// *************************************************************************** *
// *                                                                           *
// *                      Mentor Graphics Corporation                          *
// *                          All rights reserved                              *
// *                                                                           *
// *************************************************************************** *
// *                                                                           *
// * Description:         CANDB File                                           *
// * Generated at:        2021-02-26 13:32                                     *
// * System:              SPA4710_Final2                                       *
// * Variant:             ConfigurationsSPA3AD_prototype                       *
// * Network:             Mid6CANFD                                            *
// *                                                                           *
// *************************************************************************** *
// *                                                                           *
// *             THIS CONFIGURATION MIGHT CONTAIN SOME ERRORS                  *
// *              IF THE INPUT MODEL WAS NOT PROPERLY FORMED!                  *
// *                    Do Not Use this File directly!                         *
// *                                                                           *
// *************************************************************************** *
VERSION "Mid6CANFD"

NS_ :

BS_ :

BU_ :  ETC SSMB VIMB

BO_ 283 VIMBMid6CanFdFr22 : 64 VIMB
 SG_ AdSecPSSGroupSafe3_UB : 511|1@0+ (1,0) [0|1] "" SSMB
 SG_ AdSecPSSGroupSafe3Chks : 0|16@1+ (1.0,0.0) [0.0|65535.0] "Unitless" SSMB
 SG_ AdSecPSSGroupSafe3Cntr : 16|8@1+ (1.0,0.0) [0.0|255.0] "Unitless" SSMB
 SG_ AdSecPSSGroupSafe3DataID : 24|16@1+ (1.0,0.0) [0.0|65535.0] "Unitless" SSMB
 SG_ AdSecPSSGroupSafe3DeltaTPos1 : 40|18@1+ (0.000001,0.0) [0.0|0.262] "s" SSMB
 SG_ AdSecPSSGroupSafe3DeltaTPos2 : 64|18@1+ (0.000001,0.0) [0.0|0.262] "s" SSMB
 SG_ AdSecPSSGroupSafe3DeltaTPos3 : 88|18@1+ (0.000001,0.0) [0.0|0.262] "s" SSMB
 SG_ AdSecPSSGroupSafe3DeltaTPos4 : 112|18@1+ (0.000001,0.0) [0.0|0.262] "s" SSMB
 SG_ AdSecPSSGroupSafe3DeltaTPos5 : 136|18@1+ (0.000001,0.0) [0.0|0.262] "s" SSMB
 SG_ AdSecPSSGroupSafe3DeltaTPos6 : 160|18@1+ (0.000001,0.0) [0.0|0.262] "s" SSMB
 SG_ AdSecPSSGroupSafe3DeltaXPos1 : 184|18@1+ (0.0001,-13.107) [-13.107|13.107000000000003] "m" SSMB
 SG_ AdSecPSSGroupSafe3DeltaXPos2 : 202|18@1+ (0.0001,-13.107) [-13.107|13.107000000000003] "m" SSMB
 SG_ AdSecPSSGroupSafe3DeltaXPos3 : 220|18@1+ (0.0001,-13.107) [-13.107|13.107000000000003] "m" SSMB
 SG_ AdSecPSSGroupSafe3DeltaXPos4 : 238|18@1+ (0.0001,-13.107) [-13.107|13.107000000000003] "m" SSMB
 SG_ AdSecPSSGroupSafe3DeltaXPos5 : 256|18@1+ (0.0001,-13.107) [-13.107|13.107000000000003] "m" SSMB
 SG_ AdSecPSSGroupSafe3DeltaXPos6 : 274|18@1+ (0.0001,-13.107) [-13.107|13.107000000000003] "m" SSMB
 SG_ AdSecPSSGroupSafe3DeltaYPos1 : 292|18@1+ (0.0001,-13.107) [-13.107|13.107000000000003] "m" SSMB
 SG_ AdSecPSSGroupSafe3DeltaYPos2 : 310|18@1+ (0.0001,-13.107) [-13.107|13.107000000000003] "m" SSMB
 SG_ AdSecPSSGroupSafe3DeltaYPos3 : 328|18@1+ (0.0001,-13.107) [-13.107|13.107000000000003] "m" SSMB
 SG_ AdSecPSSGroupSafe3DeltaYPos4 : 346|18@1+ (0.0001,-13.107) [-13.107|13.107000000000003] "m" SSMB
 SG_ AdSecPSSGroupSafe3DeltaYPos5 : 364|18@1+ (0.0001,-13.107) [-13.107|13.107000000000003] "m" SSMB
 SG_ AdSecPSSGroupSafe3DeltaYPos6 : 382|18@1+ (0.0001,-13.107) [-13.107|13.107000000000003] "m" SSMB
 SG_ AdSecPSSGroupSafe3HeadingPos1 : 400|16@1+ (0.0001,-3.2767) [-3.2767|3.2768000000000006] "rad" SSMB
 SG_ AdSecPSSGroupSafe3HeadingPos2 : 416|16@1+ (0.0001,-3.2767) [-3.2767|3.2768000000000006] "rad" SSMB
 SG_ AdSecPSSGroupSafe3HeadingPos3 : 432|16@1+ (0.0001,-3.2767) [-3.2767|3.2768000000000006] "rad" SSMB
 SG_ AdSecPSSGroupSafe3HeadingPos4 : 448|16@1+ (0.0001,-3.2767) [-3.2767|3.2768000000000006] "rad" SSMB
 SG_ AdSecPSSGroupSafe3HeadingPos5 : 464|16@1+ (0.0001,-3.2767) [-3.2767|3.2768000000000006] "rad" SSMB
 SG_ AdSecPSSGroupSafe3HeadingPos6 : 480|16@1+ (0.0001,-3.2767) [-3.2767|3.2768000000000006] "rad" SSMB
 SG_ AdSecPSSGroupSafe3TrajectID : 496|4@1+ (1.0,0.0) [0.0|15.0] "Unitless" SSMB

BO_ 286 VIMBMid6CanFdFr23 : 64 VIMB
 SG_ AdSecPSSGroupSafe4_UB : 511|1@0+ (1,0) [0|1] "" SSMB
 SG_ AdSecPSSGroupSafe4Chks : 0|16@1+ (1.0,0.0) [0.0|65535.0] "Unitless" SSMB
 SG_ AdSecPSSGroupSafe4Cntr : 16|8@1+ (1.0,0.0) [0.0|255.0] "Unitless" SSMB
 SG_ AdSecPSSGroupSafe4DataID : 24|16@1+ (1.0,0.0) [0.0|65535.0] "Unitless" SSMB
 SG_ AdSecPSSGroupSafe4DeltaTPos1 : 40|18@1+ (0.000001,0.0) [0.0|0.262] "s" SSMB
 SG_ AdSecPSSGroupSafe4DeltaTPos2 : 64|18@1+ (0.000001,0.0) [0.0|0.262] "s" SSMB
 SG_ AdSecPSSGroupSafe4DeltaTPos3 : 88|18@1+ (0.000001,0.0) [0.0|0.262] "s" SSMB
 SG_ AdSecPSSGroupSafe4DeltaTPos4 : 112|18@1+ (0.000001,0.0) [0.0|0.262] "s" SSMB
 SG_ AdSecPSSGroupSafe4DeltaTPos5 : 136|18@1+ (0.000001,0.0) [0.0|0.262] "s" SSMB
 SG_ AdSecPSSGroupSafe4DeltaTPos6 : 160|18@1+ (0.000001,0.0) [0.0|0.262] "s" SSMB
 SG_ AdSecPSSGroupSafe4DeltaXPos1 : 184|18@1+ (0.0001,-13.107) [-13.107|13.107000000000003] "m" SSMB
 SG_ AdSecPSSGroupSafe4DeltaXPos2 : 202|18@1+ (0.0001,-13.107) [-13.107|13.107000000000003] "m" SSMB
 SG_ AdSecPSSGroupSafe4DeltaXPos3 : 220|18@1+ (0.0001,-13.107) [-13.107|13.107000000000003] "m" SSMB
 SG_ AdSecPSSGroupSafe4DeltaXPos4 : 238|18@1+ (0.0001,-13.107) [-13.107|13.107000000000003] "m" SSMB
 SG_ AdSecPSSGroupSafe4DeltaXPos5 : 256|18@1+ (0.0001,-13.107) [-13.107|13.107000000000003] "m" SSMB
 SG_ AdSecPSSGroupSafe4DeltaXPos6 : 274|18@1+ (0.0001,-13.107) [-13.107|13.107000000000003] "m" SSMB
 SG_ AdSecPSSGroupSafe4DeltaYPos1 : 292|18@1+ (0.0001,-13.107) [-13.107|13.107000000000003] "m" SSMB
 SG_ AdSecPSSGroupSafe4DeltaYPos2 : 310|18@1+ (0.0001,-13.107) [-13.107|13.107000000000003] "m" SSMB
 SG_ AdSecPSSGroupSafe4DeltaYPos3 : 328|18@1+ (0.0001,-13.107) [-13.107|13.107000000000003] "m" SSMB
 SG_ AdSecPSSGroupSafe4DeltaYPos4 : 346|18@1+ (0.0001,-13.107) [-13.107|13.107000000000003] "m" SSMB
 SG_ AdSecPSSGroupSafe4DeltaYPos5 : 364|18@1+ (0.0001,-13.107) [-13.107|13.107000000000003] "m" SSMB
 SG_ AdSecPSSGroupSafe4DeltaYPos6 : 382|18@1+ (0.0001,-13.107) [-13.107|13.107000000000003] "m" SSMB
 SG_ AdSecPSSGroupSafe4HeadingPos1 : 400|16@1+ (0.0001,-3.2767) [-3.2767|3.2768000000000006] "rad" SSMB
 SG_ AdSecPSSGroupSafe4HeadingPos2 : 416|16@1+ (0.0001,-3.2767) [-3.2767|3.2768000000000006] "rad" SSMB
 SG_ AdSecPSSGroupSafe4HeadingPos3 : 432|16@1+ (0.0001,-3.2767) [-3.2767|3.2768000000000006] "rad" SSMB
 SG_ AdSecPSSGroupSafe4HeadingPos4 : 448|16@1+ (0.0001,-3.2767) [-3.2767|3.2768000000000006] "rad" SSMB
 SG_ AdSecPSSGroupSafe4HeadingPos5 : 464|16@1+ (0.0001,-3.2767) [-3.2767|3.2768000000000006] "rad" SSMB
 SG_ AdSecPSSGroupSafe4HeadingPos6 : 480|16@1+ (0.0001,-3.2767) [-3.2767|3.2768000000000006] "rad" SSMB
 SG_ AdSecPSSGroupSafe4TrajectID : 496|4@1+ (1.0,0.0) [0.0|15.0] "Unitless" SSMB

BO_ 289 VIMBMid6CanFdFr24 : 64 VIMB
 SG_ AdSecPSSGroupSafe5_UB : 511|1@0+ (1,0) [0|1] "" SSMB
 SG_ AdSecPSSGroupSafe5Chks : 0|16@1+ (1.0,0.0) [0.0|65535.0] "Unitless" SSMB
 SG_ AdSecPSSGroupSafe5Cntr : 16|8@1+ (1.0,0.0) [0.0|255.0] "Unitless" SSMB
 SG_ AdSecPSSGroupSafe5DataID : 24|16@1+ (1.0,0.0) [0.0|65535.0] "Unitless" SSMB
 SG_ AdSecPSSGroupSafe5DeltaTPos1 : 40|18@1+ (0.000001,0.0) [0.0|0.262] "s" SSMB
 SG_ AdSecPSSGroupSafe5DeltaTPos2 : 64|18@1+ (0.000001,0.0) [0.0|0.262] "s" SSMB
 SG_ AdSecPSSGroupSafe5DeltaTPos3 : 88|18@1+ (0.000001,0.0) [0.0|0.262] "s" SSMB
 SG_ AdSecPSSGroupSafe5DeltaTPos4 : 112|18@1+ (0.000001,0.0) [0.0|0.262] "s" SSMB
 SG_ AdSecPSSGroupSafe5DeltaTPos5 : 136|18@1+ (0.000001,0.0) [0.0|0.262] "s" SSMB
 SG_ AdSecPSSGroupSafe5DeltaTPos6 : 160|18@1+ (0.000001,0.0) [0.0|0.262] "s" SSMB
 SG_ AdSecPSSGroupSafe5DeltaXPos1 : 184|18@1+ (0.0001,-13.107) [-13.107|13.107000000000003] "m" SSMB
 SG_ AdSecPSSGroupSafe5DeltaXPos2 : 202|18@1+ (0.0001,-13.107) [-13.107|13.107000000000003] "m" SSMB
 SG_ AdSecPSSGroupSafe5DeltaXPos3 : 220|18@1+ (0.0001,-13.107) [-13.107|13.107000000000003] "m" SSMB
 SG_ AdSecPSSGroupSafe5DeltaXPos4 : 238|18@1+ (0.0001,-13.107) [-13.107|13.107000000000003] "m" SSMB
 SG_ AdSecPSSGroupSafe5DeltaXPos5 : 256|18@1+ (0.0001,-13.107) [-13.107|13.107000000000003] "m" SSMB
 SG_ AdSecPSSGroupSafe5DeltaXPos6 : 274|18@1+ (0.0001,-13.107) [-13.107|13.107000000000003] "m" SSMB
 SG_ AdSecPSSGroupSafe5DeltaYPos1 : 292|18@1+ (0.0001,-13.107) [-13.107|13.107000000000003] "m" SSMB
 SG_ AdSecPSSGroupSafe5DeltaYPos2 : 310|18@1+ (0.0001,-13.107) [-13.107|13.107000000000003] "m" SSMB
 SG_ AdSecPSSGroupSafe5DeltaYPos3 : 328|18@1+ (0.0001,-13.107) [-13.107|13.107000000000003] "m" SSMB
 SG_ AdSecPSSGroupSafe5DeltaYPos4 : 346|18@1+ (0.0001,-13.107) [-13.107|13.107000000000003] "m" SSMB
 SG_ AdSecPSSGroupSafe5DeltaYPos5 : 364|18@1+ (0.0001,-13.107) [-13.107|13.107000000000003] "m" SSMB
 SG_ AdSecPSSGroupSafe5DeltaYPos6 : 382|18@1+ (0.0001,-13.107) [-13.107|13.107000000000003] "m" SSMB
 SG_ AdSecPSSGroupSafe5HeadingPos1 : 400|16@1+ (0.0001,-3.2767) [-3.2767|3.2768000000000006] "rad" SSMB
 SG_ AdSecPSSGroupSafe5HeadingPos2 : 416|16@1+ (0.0001,-3.2767) [-3.2767|3.2768000000000006] "rad" SSMB
 SG_ AdSecPSSGroupSafe5HeadingPos3 : 432|16@1+ (0.0001,-3.2767) [-3.2767|3.2768000000000006] "rad" SSMB
 SG_ AdSecPSSGroupSafe5HeadingPos4 : 448|16@1+ (0.0001,-3.2767) [-3.2767|3.2768000000000006] "rad" SSMB
 SG_ AdSecPSSGroupSafe5HeadingPos5 : 464|16@1+ (0.0001,-3.2767) [-3.2767|3.2768000000000006] "rad" SSMB
 SG_ AdSecPSSGroupSafe5HeadingPos6 : 480|16@1+ (0.0001,-3.2767) [-3.2767|3.2768000000000006] "rad" SSMB
 SG_ AdSecPSSGroupSafe5TrajectID : 496|4@1+ (1.0,0.0) [0.0|15.0] "Unitless" SSMB

BO_ 292 VIMBMid6CanFdFr25 : 64 VIMB
 SG_ AdSecPSSGroupSafe6_UB : 511|1@0+ (1,0) [0|1] "" SSMB
 SG_ AdSecPSSGroupSafe6Chks : 0|16@1+ (1.0,0.0) [0.0|65535.0] "Unitless" SSMB
 SG_ AdSecPSSGroupSafe6Cntr : 16|8@1+ (1.0,0.0) [0.0|255.0] "Unitless" SSMB
 SG_ AdSecPSSGroupSafe6DataID : 24|16@1+ (1.0,0.0) [0.0|65535.0] "Unitless" SSMB
 SG_ AdSecPSSGroupSafe6DeltaTPos1 : 40|18@1+ (0.000001,0.0) [0.0|0.262] "s" SSMB
 SG_ AdSecPSSGroupSafe6DeltaTPos2 : 64|18@1+ (0.000001,0.0) [0.0|0.262] "s" SSMB
 SG_ AdSecPSSGroupSafe6DeltaTPos3 : 88|18@1+ (0.000001,0.0) [0.0|0.262] "s" SSMB
 SG_ AdSecPSSGroupSafe6DeltaTPos4 : 112|18@1+ (0.000001,0.0) [0.0|0.262] "s" SSMB
 SG_ AdSecPSSGroupSafe6DeltaTPos5 : 136|18@1+ (0.000001,0.0) [0.0|0.262] "s" SSMB
 SG_ AdSecPSSGroupSafe6DeltaTPos6 : 160|18@1+ (0.000001,0.0) [0.0|0.262] "s" SSMB
 SG_ AdSecPSSGroupSafe6DeltaXPos1 : 184|18@1+ (0.0001,-13.107) [-13.107|13.107000000000003] "m" SSMB
 SG_ AdSecPSSGroupSafe6DeltaXPos2 : 202|18@1+ (0.0001,-13.107) [-13.107|13.107000000000003] "m" SSMB
 SG_ AdSecPSSGroupSafe6DeltaXPos3 : 220|18@1+ (0.0001,-13.107) [-13.107|13.107000000000003] "m" SSMB
 SG_ AdSecPSSGroupSafe6DeltaXPos4 : 238|18@1+ (0.0001,-13.107) [-13.107|13.107000000000003] "m" SSMB
 SG_ AdSecPSSGroupSafe6DeltaXPos5 : 256|18@1+ (0.0001,-13.107) [-13.107|13.107000000000003] "m" SSMB
 SG_ AdSecPSSGroupSafe6DeltaXPos6 : 274|18@1+ (0.0001,-13.107) [-13.107|13.107000000000003] "m" SSMB
 SG_ AdSecPSSGroupSafe6DeltaYPos1 : 292|18@1+ (0.0001,-13.107) [-13.107|13.107000000000003] "m" SSMB
 SG_ AdSecPSSGroupSafe6DeltaYPos2 : 310|18@1+ (0.0001,-13.107) [-13.107|13.107000000000003] "m" SSMB
 SG_ AdSecPSSGroupSafe6DeltaYPos3 : 328|18@1+ (0.0001,-13.107) [-13.107|13.107000000000003] "m" SSMB
 SG_ AdSecPSSGroupSafe6DeltaYPos4 : 346|18@1+ (0.0001,-13.107) [-13.107|13.107000000000003] "m" SSMB
 SG_ AdSecPSSGroupSafe6DeltaYPos5 : 364|18@1+ (0.0001,-13.107) [-13.107|13.107000000000003] "m" SSMB
 SG_ AdSecPSSGroupSafe6DeltaYPos6 : 382|18@1+ (0.0001,-13.107) [-13.107|13.107000000000003] "m" SSMB
 SG_ AdSecPSSGroupSafe6HeadingPos1 : 400|16@1+ (0.0001,-3.2767) [-3.2767|3.2768000000000006] "rad" SSMB
 SG_ AdSecPSSGroupSafe6HeadingPos2 : 416|16@1+ (0.0001,-3.2767) [-3.2767|3.2768000000000006] "rad" SSMB
 SG_ AdSecPSSGroupSafe6HeadingPos3 : 432|16@1+ (0.0001,-3.2767) [-3.2767|3.2768000000000006] "rad" SSMB
 SG_ AdSecPSSGroupSafe6HeadingPos4 : 448|16@1+ (0.0001,-3.2767) [-3.2767|3.2768000000000006] "rad" SSMB
 SG_ AdSecPSSGroupSafe6HeadingPos5 : 464|16@1+ (0.0001,-3.2767) [-3.2767|3.2768000000000006] "rad" SSMB
 SG_ AdSecPSSGroupSafe6HeadingPos6 : 480|16@1+ (0.0001,-3.2767) [-3.2767|3.2768000000000006] "rad" SSMB
 SG_ AdSecPSSGroupSafe6TrajectID : 496|4@1+ (1.0,0.0) [0.0|15.0] "Unitless" SSMB

BO_ 295 VIMBMid6CanFdFr26 : 64 VIMB
 SG_ AdSecPSSGroupSafe7_UB : 511|1@0+ (1,0) [0|1] "" SSMB
 SG_ AdSecPSSGroupSafe7Chks : 0|16@1+ (1.0,0.0) [0.0|65535.0] "Unitless" SSMB
 SG_ AdSecPSSGroupSafe7Cntr : 16|8@1+ (1.0,0.0) [0.0|255.0] "Unitless" SSMB
 SG_ AdSecPSSGroupSafe7DataID : 24|16@1+ (1.0,0.0) [0.0|65535.0] "Unitless" SSMB
 SG_ AdSecPSSGroupSafe7DeltaTPos1 : 40|18@1+ (0.000001,0.0) [0.0|0.262] "s" SSMB
 SG_ AdSecPSSGroupSafe7DeltaTPos2 : 64|18@1+ (0.000001,0.0) [0.0|0.262] "s" SSMB
 SG_ AdSecPSSGroupSafe7DeltaTPos3 : 88|18@1+ (0.000001,0.0) [0.0|0.262] "s" SSMB
 SG_ AdSecPSSGroupSafe7DeltaTPos4 : 112|18@1+ (0.000001,0.0) [0.0|0.262] "s" SSMB
 SG_ AdSecPSSGroupSafe7DeltaTPos5 : 136|18@1+ (0.000001,0.0) [0.0|0.262] "s" SSMB
 SG_ AdSecPSSGroupSafe7DeltaTPos6 : 160|18@1+ (0.000001,0.0) [0.0|0.262] "s" SSMB
 SG_ AdSecPSSGroupSafe7DeltaXPos1 : 184|18@1+ (0.0001,-13.107) [-13.107|13.107000000000003] "m" SSMB
 SG_ AdSecPSSGroupSafe7DeltaXPos2 : 202|18@1+ (0.0001,-13.107) [-13.107|13.107000000000003] "m" SSMB
 SG_ AdSecPSSGroupSafe7DeltaXPos3 : 220|18@1+ (0.0001,-13.107) [-13.107|13.107000000000003] "m" SSMB
 SG_ AdSecPSSGroupSafe7DeltaXPos4 : 238|18@1+ (0.0001,-13.107) [-13.107|13.107000000000003] "m" SSMB
 SG_ AdSecPSSGroupSafe7DeltaXPos5 : 256|18@1+ (0.0001,-13.107) [-13.107|13.107000000000003] "m" SSMB
 SG_ AdSecPSSGroupSafe7DeltaXPos6 : 274|18@1+ (0.0001,-13.107) [-13.107|13.107000000000003] "m" SSMB
 SG_ AdSecPSSGroupSafe7DeltaYPos1 : 292|18@1+ (0.0001,-13.107) [-13.107|13.107000000000003] "m" SSMB
 SG_ AdSecPSSGroupSafe7DeltaYPos2 : 310|18@1+ (0.0001,-13.107) [-13.107|13.107000000000003] "m" SSMB
 SG_ AdSecPSSGroupSafe7DeltaYPos3 : 328|18@1+ (0.0001,-13.107) [-13.107|13.107000000000003] "m" SSMB
 SG_ AdSecPSSGroupSafe7DeltaYPos4 : 346|18@1+ (0.0001,-13.107) [-13.107|13.107000000000003] "m" SSMB
 SG_ AdSecPSSGroupSafe7DeltaYPos5 : 364|18@1+ (0.0001,-13.107) [-13.107|13.107000000000003] "m" SSMB
 SG_ AdSecPSSGroupSafe7DeltaYPos6 : 382|18@1+ (0.0001,-13.107) [-13.107|13.107000000000003] "m" SSMB
 SG_ AdSecPSSGroupSafe7HeadingPos1 : 400|16@1+ (0.0001,-3.2767) [-3.2767|3.2768000000000006] "rad" SSMB
 SG_ AdSecPSSGroupSafe7HeadingPos2 : 416|16@1+ (0.0001,-3.2767) [-3.2767|3.2768000000000006] "rad" SSMB
 SG_ AdSecPSSGroupSafe7HeadingPos3 : 432|16@1+ (0.0001,-3.2767) [-3.2767|3.2768000000000006] "rad" SSMB
 SG_ AdSecPSSGroupSafe7HeadingPos4 : 448|16@1+ (0.0001,-3.2767) [-3.2767|3.2768000000000006] "rad" SSMB
 SG_ AdSecPSSGroupSafe7HeadingPos5 : 464|16@1+ (0.0001,-3.2767) [-3.2767|3.2768000000000006] "rad" SSMB
 SG_ AdSecPSSGroupSafe7HeadingPos6 : 480|16@1+ (0.0001,-3.2767) [-3.2767|3.2768000000000006] "rad" SSMB
 SG_ AdSecPSSGroupSafe7TrajectID : 496|4@1+ (1.0,0.0) [0.0|15.0] "Unitless" SSMB

BO_ 296 VIMBMid6CanFdFr27 : 64 VIMB
 SG_ AdSecPSSGroupSafe8_UB : 511|1@0+ (1,0) [0|1] "" SSMB
 SG_ AdSecPSSGroupSafe8Chks : 0|16@1+ (1.0,0.0) [0.0|65535.0] "Unitless" SSMB
 SG_ AdSecPSSGroupSafe8Cntr : 16|8@1+ (1.0,0.0) [0.0|255.0] "Unitless" SSMB
 SG_ AdSecPSSGroupSafe8DataID : 24|16@1+ (1.0,0.0) [0.0|65535.0] "Unitless" SSMB
 SG_ AdSecPSSGroupSafe8DeltaTPos1 : 40|18@1+ (0.000001,0.0) [0.0|0.262] "s" SSMB
 SG_ AdSecPSSGroupSafe8DeltaTPos2 : 64|18@1+ (0.000001,0.0) [0.0|0.262] "s" SSMB
 SG_ AdSecPSSGroupSafe8DeltaTPos3 : 88|18@1+ (0.000001,0.0) [0.0|0.262] "s" SSMB
 SG_ AdSecPSSGroupSafe8DeltaTPos4 : 112|18@1+ (0.000001,0.0) [0.0|0.262] "s" SSMB
 SG_ AdSecPSSGroupSafe8DeltaTPos5 : 136|18@1+ (0.000001,0.0) [0.0|0.262] "s" SSMB
 SG_ AdSecPSSGroupSafe8DeltaTPos6 : 160|18@1+ (0.000001,0.0) [0.0|0.262] "s" SSMB
 SG_ AdSecPSSGroupSafe8DeltaXPos1 : 184|18@1+ (0.0001,-13.107) [-13.107|13.107000000000003] "m" SSMB
 SG_ AdSecPSSGroupSafe8DeltaXPos2 : 202|18@1+ (0.0001,-13.107) [-13.107|13.107000000000003] "m" SSMB
 SG_ AdSecPSSGroupSafe8DeltaXPos3 : 220|18@1+ (0.0001,-13.107) [-13.107|13.107000000000003] "m" SSMB
 SG_ AdSecPSSGroupSafe8DeltaXPos4 : 238|18@1+ (0.0001,-13.107) [-13.107|13.107000000000003] "m" SSMB
 SG_ AdSecPSSGroupSafe8DeltaXPos5 : 256|18@1+ (0.0001,-13.107) [-13.107|13.107000000000003] "m" SSMB
 SG_ AdSecPSSGroupSafe8DeltaXPos6 : 274|18@1+ (0.0001,-13.107) [-13.107|13.107000000000003] "m" SSMB
 SG_ AdSecPSSGroupSafe8DeltaYPos1 : 292|18@1+ (0.0001,-13.107) [-13.107|13.107000000000003] "m" SSMB
 SG_ AdSecPSSGroupSafe8DeltaYPos2 : 310|18@1+ (0.0001,-13.107) [-13.107|13.107000000000003] "m" SSMB
 SG_ AdSecPSSGroupSafe8DeltaYPos3 : 328|18@1+ (0.0001,-13.107) [-13.107|13.107000000000003] "m" SSMB
 SG_ AdSecPSSGroupSafe8DeltaYPos4 : 346|18@1+ (0.0001,-13.107) [-13.107|13.107000000000003] "m" SSMB
 SG_ AdSecPSSGroupSafe8DeltaYPos5 : 364|18@1+ (0.0001,-13.107) [-13.107|13.107000000000003] "m" SSMB
 SG_ AdSecPSSGroupSafe8DeltaYPos6 : 382|18@1+ (0.0001,-13.107) [-13.107|13.107000000000003] "m" SSMB
 SG_ AdSecPSSGroupSafe8HeadingPos1 : 400|16@1+ (0.0001,-3.2767) [-3.2767|3.2768000000000006] "rad" SSMB
 SG_ AdSecPSSGroupSafe8HeadingPos2 : 416|16@1+ (0.0001,-3.2767) [-3.2767|3.2768000000000006] "rad" SSMB
 SG_ AdSecPSSGroupSafe8HeadingPos3 : 432|16@1+ (0.0001,-3.2767) [-3.2767|3.2768000000000006] "rad" SSMB
 SG_ AdSecPSSGroupSafe8HeadingPos4 : 448|16@1+ (0.0001,-3.2767) [-3.2767|3.2768000000000006] "rad" SSMB
 SG_ AdSecPSSGroupSafe8HeadingPos5 : 464|16@1+ (0.0001,-3.2767) [-3.2767|3.2768000000000006] "rad" SSMB
 SG_ AdSecPSSGroupSafe8HeadingPos6 : 480|16@1+ (0.0001,-3.2767) [-3.2767|3.2768000000000006] "rad" SSMB
 SG_ AdSecPSSGroupSafe8TrajectID : 496|4@1+ (1.0,0.0) [0.0|15.0] "Unitless" SSMB

BO_ 80 VIMBMid6CanFdFr28 : 16 VIMB
 SG_ AdSecALgtLimReqGroupSafe_UB : 4|1@0+ (1,0) [0|1] "" SSMB
 SG_ AdSecALgtLimReqGroupSafeALgtMaxReq : 3|12@0+ (0.0078125,-15.0) [-15.0|15.0] "m/s^2" SSMB
 SG_ AdSecALgtLimReqGroupSafeALgtMinReq : 19|12@0+ (0.0078125,-15.0) [-15.0|15.0] "m/s^2" SSMB
 SG_ AdSecALgtLimReqGroupSafeChks : 39|8@0+ (1.0,0.0) [0.0|255.0] "Unitless" SSMB
 SG_ AdSecALgtLimReqGroupSafeCntr : 23|4@0+ (1.0,0.0) [0.0|15.0] "Unitless" SSMB
 SG_ SecAdNomALgtReqGroupSafe_UB : 5|1@0+ (1,0) [0|1] "" SSMB
 SG_ SecAdNomALgtReqGroupSafeALgtNomReqMax : 43|12@0+ (0.0078125,-15.0) [-15.0|15.0] "m/s^2" SSMB
 SG_ SecAdNomALgtReqGroupSafeALgtNomReqMin : 59|12@0+ (0.0078125,-15.0) [-15.0|15.0] "m/s^2" SSMB
 SG_ SecAdNomALgtReqGroupSafeChks : 79|8@0+ (1.0,0.0) [0.0|255.0] "Unitless" SSMB
 SG_ SecAdNomALgtReqGroupSafeCntr : 63|4@0+ (1.0,0.0) [0.0|15.0] "Unitless" SSMB
 SG_ SecAdNomALgtReqGroupSafeNegLimForJerk : 83|12@0+ (0.05,-100.0) [-100.0|100.0] "m/s^3" SSMB
 SG_ SecAdNomALgtReqGroupSafePosLimForJerk : 99|12@0+ (0.05,-100.0) [-100.0|100.0] "m/s^3" SSMB

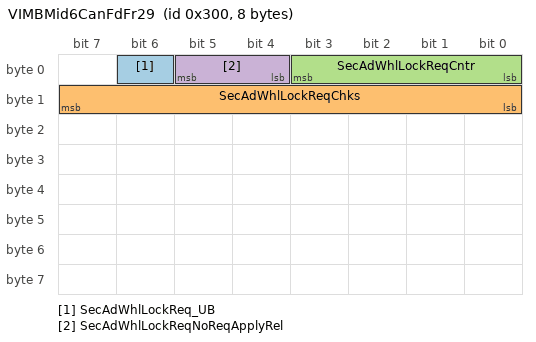
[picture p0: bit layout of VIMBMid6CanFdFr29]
BO_ 768 VIMBMid6CanFdFr29 : 8 VIMB
 SG_ SecAdWhlLockReq_UB : 6|1@0+ (1,0) [0|1] "" SSMB
 SG_ SecAdWhlLockReqChks : 15|8@0+ (1.0,0.0) [0.0|255.0] "Unitless" SSMB
 SG_ SecAdWhlLockReqCntr : 3|4@0+ (1.0,0.0) [0.0|15.0] "Unitless" SSMB
 SG_ SecAdWhlLockReqNoReqApplyRel : 5|2@0+ (1,0) [0|3] "" SSMB

BO_ 64 VimbMid6CanFdTimeSynchFr : 8 VIMB

BO_ 40 VIMBPrototypeMid6CanFdFr29 : 12 VIMB
 SG_ SecMonTiSyncMsg_UB : 75|1@0+ (1,0) [0|1] "" SSMB
 SG_ SecMonTiSyncMsgChks : 71|8@0+ (1.0,0.0) [0.0|255.0] "Unitless" SSMB
 SG_ SecMonTiSyncMsgCntr : 79|4@0+ (1.0,0.0) [0.0|15.0] "Unitless" SSMB
 SG_ SecMonTiSyncMsgTiStampNanoSec : 7|32@0+ (1.0,0.0) [0.0|4294967295.0] "Unitless" SSMB
 SG_ SecMonTiSyncMsgTiStampSec : 39|32@0+ (1.0,0.0) [0.0|4294967295.0] "Unitless" SSMB

CM_ SG_ 283 AdSecPSSGroupSafe3Chks "Platform Safe Stop buffer paths. 

All signalgroups cover 50 points + 1 initial point. Each point has delta X, Y, time and heading. All signal groups are tied together with a trajectory id. 
All signalgroups include signals for E2E protection using profile 5 according to Autosar 4.2.2.

Signal group 3 includes:
* 6 PSS points, with overall sequence 15-20
 E2E checksum, profile 5";
CM_ SG_ 283 AdSecPSSGroupSafe3Cntr "Platform Safe Stop buffer paths. 

All signalgroups cover 50 points + 1 initial point. Each point has delta X, Y, time and heading. All signal groups are tied together with a trajectory id. 
All signalgroups include signals for E2E protection using profile 5 according to Autosar 4.2.2.

Signal group 3 includes:
* 6 PSS points, with overall sequence 15-20
 E2E counter, profile 5";
CM_ SG_ 283 AdSecPSSGroupSafe3DataID "Platform Safe Stop buffer paths. 

All signalgroups cover 50 points + 1 initial point. Each point has delta X, Y, time and heading. All signal groups are tied together with a trajectory id. 
All signalgroups include signals for E2E protection using profile 5 according to Autosar 4.2.2.

Signal group 3 includes:
* 6 PSS points, with overall sequence 15-20
 E2E Data ID, profile 5";
CM_ SG_ 283 AdSecPSSGroupSafe3DeltaTPos1 "Platform Safe Stop buffer paths. 

All signalgroups cover 50 points + 1 initial point. Each point has delta X, Y, time and heading. All signal groups are tied together with a trajectory id. 
All signalgroups include signals for E2E protection using profile 5 according to Autosar 4.2.2.

Signal group 3 includes:
* 6 PSS points, with overall sequence 15-20
 Delta time position 1";
CM_ SG_ 283 AdSecPSSGroupSafe3DeltaTPos2 "Platform Safe Stop buffer paths. 

All signalgroups cover 50 points + 1 initial point. Each point has delta X, Y, time and heading. All signal groups are tied together with a trajectory id. 
All signalgroups include signals for E2E protection using profile 5 according to Autosar 4.2.2.

Signal group 3 includes:
* 6 PSS points, with overall sequence 15-20
 Delta time position 2";
CM_ SG_ 283 AdSecPSSGroupSafe3DeltaTPos3 "Platform Safe Stop buffer paths. 

All signalgroups cover 50 points + 1 initial point. Each point has delta X, Y, time and heading. All signal groups are tied together with a trajectory id. 
All signalgroups include signals for E2E protection using profile 5 according to Autosar 4.2.2.

Signal group 3 includes:
* 6 PSS points, with overall sequence 15-20
 Delta time position 3";
CM_ SG_ 283 AdSecPSSGroupSafe3DeltaTPos4 "Platform Safe Stop buffer paths. 

All signalgroups cover 50 points + 1 initial point. Each point has delta X, Y, time and heading. All signal groups are tied together with a trajectory id. 
All signalgroups include signals for E2E protection using profile 5 according to Autosar 4.2.2.

Signal group 3 includes:
* 6 PSS points, with overall sequence 15-20
 Delta time position 4";
CM_ SG_ 283 AdSecPSSGroupSafe3DeltaTPos5 "Platform Safe Stop buffer paths. 

All signalgroups cover 50 points + 1 initial point. Each point has delta X, Y, time and heading. All signal groups are tied together with a trajectory id. 
All signalgroups include signals for E2E protection using profile 5 according to Autosar 4.2.2.

Signal group 3 includes:
* 6 PSS points, with overall sequence 15-20
 Delta time position 5";
CM_ SG_ 283 AdSecPSSGroupSafe3DeltaTPos6 "Platform Safe Stop buffer paths. 

All signalgroups cover 50 points + 1 initial point. Each point has delta X, Y, time and heading. All signal groups are tied together with a trajectory id. 
All signalgroups include signals for E2E protection using profile 5 according to Autosar 4.2.2.

Signal group 3 includes:
* 6 PSS points, with overall sequence 15-20
 Delta time position 6";
CM_ SG_ 283 AdSecPSSGroupSafe3DeltaXPos1 "Platform Safe Stop buffer paths. 

All signalgroups cover 50 points + 1 initial point. Each point has delta X, Y, time and heading. All signal groups are tied together with a trajectory id. 
All signalgroups include signals for E2E protection using profile 5 according to Autosar 4.2.2.

Signal group 3 includes:
* 6 PSS points, with overall sequence 15-20
 Delta X position 1";
CM_ SG_ 283 AdSecPSSGroupSafe3DeltaXPos2 "Platform Safe Stop buffer paths. 

All signalgroups cover 50 points + 1 initial point. Each point has delta X, Y, time and heading. All signal groups are tied together with a trajectory id. 
All signalgroups include signals for E2E protection using profile 5 according to Autosar 4.2.2.

Signal group 3 includes:
* 6 PSS points, with overall sequence 15-20
 Delta X position 2";
CM_ SG_ 283 AdSecPSSGroupSafe3DeltaXPos3 "Platform Safe Stop buffer paths. 

All signalgroups cover 50 points + 1 initial point. Each point has delta X, Y, time and heading. All signal groups are tied together with a trajectory id. 
All signalgroups include signals for E2E protection using profile 5 according to Autosar 4.2.2.

Signal group 3 includes:
* 6 PSS points, with overall sequence 15-20
 Delta X position 3";
CM_ SG_ 283 AdSecPSSGroupSafe3DeltaXPos4 "Platform Safe Stop buffer paths. 

All signalgroups cover 50 points + 1 initial point. Each point has delta X, Y, time and heading. All signal groups are tied together with a trajectory id. 
All signalgroups include signals for E2E protection using profile 5 according to Autosar 4.2.2.

Signal group 3 includes:
* 6 PSS points, with overall sequence 15-20
 Delta X position 4";
CM_ SG_ 283 AdSecPSSGroupSafe3DeltaXPos5 "Platform Safe Stop buffer paths. 

All signalgroups cover 50 points + 1 initial point. Each point has delta X, Y, time and heading. All signal groups are tied together with a trajectory id. 
All signalgroups include signals for E2E protection using profile 5 according to Autosar 4.2.2.

Signal group 3 includes:
* 6 PSS points, with overall sequence 15-20
 Delta X position 5";
CM_ SG_ 283 AdSecPSSGroupSafe3DeltaXPos6 "Platform Safe Stop buffer paths. 

All signalgroups cover 50 points + 1 initial point. Each point has delta X, Y, time and heading. All signal groups are tied together with a trajectory id. 
All signalgroups include signals for E2E protection using profile 5 according to Autosar 4.2.2.

Signal group 3 includes:
* 6 PSS points, with overall sequence 15-20
 Delta X position 6";
CM_ SG_ 283 AdSecPSSGroupSafe3DeltaYPos1 "Platform Safe Stop buffer paths. 

All signalgroups cover 50 points + 1 initial point. Each point has delta X, Y, time and heading. All signal groups are tied together with a trajectory id. 
All signalgroups include signals for E2E protection using profile 5 according to Autosar 4.2.2.

Signal group 3 includes:
* 6 PSS points, with overall sequence 15-20
 Delta Y position 1";
CM_ SG_ 283 AdSecPSSGroupSafe3DeltaYPos2 "Platform Safe Stop buffer paths. 

All signalgroups cover 50 points + 1 initial point. Each point has delta X, Y, time and heading. All signal groups are tied together with a trajectory id. 
All signalgroups include signals for E2E protection using profile 5 according to Autosar 4.2.2.

Signal group 3 includes:
* 6 PSS points, with overall sequence 15-20
 Delta Y position 2";
CM_ SG_ 283 AdSecPSSGroupSafe3DeltaYPos3 "Platform Safe Stop buffer paths. 

All signalgroups cover 50 points + 1 initial point. Each point has delta X, Y, time and heading. All signal groups are tied together with a trajectory id. 
All signalgroups include signals for E2E protection using profile 5 according to Autosar 4.2.2.

Signal group 3 includes:
* 6 PSS points, with overall sequence 15-20
 Delta Y position 3";
CM_ SG_ 283 AdSecPSSGroupSafe3DeltaYPos4 "Platform Safe Stop buffer paths. 

All signalgroups cover 50 points + 1 initial point. Each point has delta X, Y, time and heading. All signal groups are tied together with a trajectory id. 
All signalgroups include signals for E2E protection using profile 5 according to Autosar 4.2.2.

Signal group 3 includes:
* 6 PSS points, with overall sequence 15-20
 Delta Y position 4";
CM_ SG_ 283 AdSecPSSGroupSafe3DeltaYPos5 "Platform Safe Stop buffer paths. 

All signalgroups cover 50 points + 1 initial point. Each point has delta X, Y, time and heading. All signal groups are tied together with a trajectory id. 
All signalgroups include signals for E2E protection using profile 5 according to Autosar 4.2.2.

Signal group 3 includes:
* 6 PSS points, with overall sequence 15-20
 Delta Y position 5";
CM_ SG_ 283 AdSecPSSGroupSafe3DeltaYPos6 "Platform Safe Stop buffer paths. 

All signalgroups cover 50 points + 1 initial point. Each point has delta X, Y, time and heading. All signal groups are tied together with a trajectory id. 
All signalgroups include signals for E2E protection using profile 5 according to Autosar 4.2.2.

Signal group 3 includes:
* 6 PSS points, with overall sequence 15-20
 Delta Y position 6";
CM_ SG_ 283 AdSecPSSGroupSafe3HeadingPos1 "Platform Safe Stop buffer paths. 

All signalgroups cover 50 points + 1 initial point. Each point has delta X, Y, time and heading. All signal groups are tied together with a trajectory id. 
All signalgroups include signals for E2E protection using profile 5 according to Autosar 4.2.2.

Signal group 3 includes:
* 6 PSS points, with overall sequence 15-20
 Heading position 1";
CM_ SG_ 283 AdSecPSSGroupSafe3HeadingPos2 "Platform Safe Stop buffer paths. 

All signalgroups cover 50 points + 1 initial point. Each point has delta X, Y, time and heading. All signal groups are tied together with a trajectory id. 
All signalgroups include signals for E2E protection using profile 5 according to Autosar 4.2.2.

Signal group 3 includes:
* 6 PSS points, with overall sequence 15-20
 Heading position 2";
CM_ SG_ 283 AdSecPSSGroupSafe3HeadingPos3 "Platform Safe Stop buffer paths. 

All signalgroups cover 50 points + 1 initial point. Each point has delta X, Y, time and heading. All signal groups are tied together with a trajectory id. 
All signalgroups include signals for E2E protection using profile 5 according to Autosar 4.2.2.

Signal group 3 includes:
* 6 PSS points, with overall sequence 15-20
 Heading position 3";
CM_ SG_ 283 AdSecPSSGroupSafe3HeadingPos4 "Platform Safe Stop buffer paths. 

All signalgroups cover 50 points + 1 initial point. Each point has delta X, Y, time and heading. All signal groups are tied together with a trajectory id. 
All signalgroups include signals for E2E protection using profile 5 according to Autosar 4.2.2.

Signal group 3 includes:
* 6 PSS points, with overall sequence 15-20
 Heading position 4";
CM_ SG_ 283 AdSecPSSGroupSafe3HeadingPos5 "Platform Safe Stop buffer paths. 

All signalgroups cover 50 points + 1 initial point. Each point has delta X, Y, time and heading. All signal groups are tied together with a trajectory id. 
All signalgroups include signals for E2E protection using profile 5 according to Autosar 4.2.2.

Signal group 3 includes:
* 6 PSS points, with overall sequence 15-20
 Heading position 5";
CM_ SG_ 283 AdSecPSSGroupSafe3HeadingPos6 "Platform Safe Stop buffer paths. 

All signalgroups cover 50 points + 1 initial point. Each point has delta X, Y, time and heading. All signal groups are tied together with a trajectory id. 
All signalgroups include signals for E2E protection using profile 5 according to Autosar 4.2.2.

Signal group 3 includes:
* 6 PSS points, with overall sequence 15-20
 Heading position 6";
CM_ SG_ 283 AdSecPSSGroupSafe3TrajectID "Platform Safe Stop buffer paths. 

All signalgroups cover 50 points + 1 initial point. Each point has delta X, Y, time and heading. All signal groups are tied together with a trajectory id. 
All signalgroups include signals for E2E protection using profile 5 according to Autosar 4.2.2.

Signal group 3 includes:
* 6 PSS points, with overall sequence 15-20
 Trajectory ID";
CM_ SG_ 286 AdSecPSSGroupSafe4Chks "Platform Safe Stop buffer paths. 

All signalgroups cover 50 points + 1 initial point. Each point has delta X, Y, time and heading. All signal groups are tied together with a trajectory id. 
All signalgroups include signals for E2E protection using profile 5 according to Autosar 4.2.2.

Signal group 4 includes:
* 6 PSS points, with overall sequence 21-26
 E2E checksum, profile 5";
CM_ SG_ 286 AdSecPSSGroupSafe4Cntr "Platform Safe Stop buffer paths. 

All signalgroups cover 50 points + 1 initial point. Each point has delta X, Y, time and heading. All signal groups are tied together with a trajectory id. 
All signalgroups include signals for E2E protection using profile 5 according to Autosar 4.2.2.

Signal group 4 includes:
* 6 PSS points, with overall sequence 21-26
 E2E counter, profile 5";
CM_ SG_ 286 AdSecPSSGroupSafe4DataID "Platform Safe Stop buffer paths. 

All signalgroups cover 50 points + 1 initial point. Each point has delta X, Y, time and heading. All signal groups are tied together with a trajectory id. 
All signalgroups include signals for E2E protection using profile 5 according to Autosar 4.2.2.

Signal group 4 includes:
* 6 PSS points, with overall sequence 21-26
 E2E Data ID, profile 5";
CM_ SG_ 286 AdSecPSSGroupSafe4DeltaTPos1 "Platform Safe Stop buffer paths. 

All signalgroups cover 50 points + 1 initial point. Each point has delta X, Y, time and heading. All signal groups are tied together with a trajectory id. 
All signalgroups include signals for E2E protection using profile 5 according to Autosar 4.2.2.

Signal group 4 includes:
* 6 PSS points, with overall sequence 21-26
 Delta time position 1";
CM_ SG_ 286 AdSecPSSGroupSafe4DeltaTPos2 "Platform Safe Stop buffer paths. 

All signalgroups cover 50 points + 1 initial point. Each point has delta X, Y, time and heading. All signal groups are tied together with a trajectory id. 
All signalgroups include signals for E2E protection using profile 5 according to Autosar 4.2.2.

Signal group 4 includes:
* 6 PSS points, with overall sequence 21-26
 Delta time position 2";
CM_ SG_ 286 AdSecPSSGroupSafe4DeltaTPos3 "Platform Safe Stop buffer paths. 

All signalgroups cover 50 points + 1 initial point. Each point has delta X, Y, time and heading. All signal groups are tied together with a trajectory id. 
All signalgroups include signals for E2E protection using profile 5 according to Autosar 4.2.2.

Signal group 4 includes:
* 6 PSS points, with overall sequence 21-26
 Delta time position 3";
CM_ SG_ 286 AdSecPSSGroupSafe4DeltaTPos4 "Platform Safe Stop buffer paths. 

All signalgroups cover 50 points + 1 initial point. Each point has delta X, Y, time and heading. All signal groups are tied together with a trajectory id. 
All signalgroups include signals for E2E protection using profile 5 according to Autosar 4.2.2.

Signal group 4 includes:
* 6 PSS points, with overall sequence 21-26
 Delta time position 4";
CM_ SG_ 286 AdSecPSSGroupSafe4DeltaTPos5 "Platform Safe Stop buffer paths. 

All signalgroups cover 50 points + 1 initial point. Each point has delta X, Y, time and heading. All signal groups are tied together with a trajectory id. 
All signalgroups include signals for E2E protection using profile 5 according to Autosar 4.2.2.

Signal group 4 includes:
* 6 PSS points, with overall sequence 21-26
 Delta time position 5";
CM_ SG_ 286 AdSecPSSGroupSafe4DeltaTPos6 "Platform Safe Stop buffer paths. 

All signalgroups cover 50 points + 1 initial point. Each point has delta X, Y, time and heading. All signal groups are tied together with a trajectory id. 
All signalgroups include signals for E2E protection using profile 5 according to Autosar 4.2.2.

Signal group 4 includes:
* 6 PSS points, with overall sequence 21-26
 Delta time position 6";
CM_ SG_ 286 AdSecPSSGroupSafe4DeltaXPos1 "Platform Safe Stop buffer paths. 

All signalgroups cover 50 points + 1 initial point. Each point has delta X, Y, time and heading. All signal groups are tied together with a trajectory id. 
All signalgroups include signals for E2E protection using profile 5 according to Autosar 4.2.2.

Signal group 4 includes:
* 6 PSS points, with overall sequence 21-26
 Delta X position 1";
CM_ SG_ 286 AdSecPSSGroupSafe4DeltaXPos2 "Platform Safe Stop buffer paths. 

All signalgroups cover 50 points + 1 initial point. Each point has delta X, Y, time and heading. All signal groups are tied together with a trajectory id. 
All signalgroups include signals for E2E protection using profile 5 according to Autosar 4.2.2.

Signal group 4 includes:
* 6 PSS points, with overall sequence 21-26
 Delta X position 2";
CM_ SG_ 286 AdSecPSSGroupSafe4DeltaXPos3 "Platform Safe Stop buffer paths. 

All signalgroups cover 50 points + 1 initial point. Each point has delta X, Y, time and heading. All signal groups are tied together with a trajectory id. 
All signalgroups include signals for E2E protection using profile 5 according to Autosar 4.2.2.

Signal group 4 includes:
* 6 PSS points, with overall sequence 21-26
 Delta X position 3";
CM_ SG_ 286 AdSecPSSGroupSafe4DeltaXPos4 "Platform Safe Stop buffer paths. 

All signalgroups cover 50 points + 1 initial point. Each point has delta X, Y, time and heading. All signal groups are tied together with a trajectory id. 
All signalgroups include signals for E2E protection using profile 5 according to Autosar 4.2.2.

Signal group 4 includes:
* 6 PSS points, with overall sequence 21-26
 Delta X position 4";
CM_ SG_ 286 AdSecPSSGroupSafe4DeltaXPos5 "Platform Safe Stop buffer paths. 

All signalgroups cover 50 points + 1 initial point. Each point has delta X, Y, time and heading. All signal groups are tied together with a trajectory id. 
All signalgroups include signals for E2E protection using profile 5 according to Autosar 4.2.2.

Signal group 4 includes:
* 6 PSS points, with overall sequence 21-26
 Delta X position 5";
CM_ SG_ 286 AdSecPSSGroupSafe4DeltaXPos6 "Platform Safe Stop buffer paths. 

All signalgroups cover 50 points + 1 initial point. Each point has delta X, Y, time and heading. All signal groups are tied together with a trajectory id. 
All signalgroups include signals for E2E protection using profile 5 according to Autosar 4.2.2.

Signal group 4 includes:
* 6 PSS points, with overall sequence 21-26
 Delta X position 6";
CM_ SG_ 286 AdSecPSSGroupSafe4DeltaYPos1 "Platform Safe Stop buffer paths. 

All signalgroups cover 50 points + 1 initial point. Each point has delta X, Y, time and heading. All signal groups are tied together with a trajectory id. 
All signalgroups include signals for E2E protection using profile 5 according to Autosar 4.2.2.

Signal group 4 includes:
* 6 PSS points, with overall sequence 21-26
 Delta Y position 1";
CM_ SG_ 286 AdSecPSSGroupSafe4DeltaYPos2 "Platform Safe Stop buffer paths. 

All signalgroups cover 50 points + 1 initial point. Each point has delta X, Y, time and heading. All signal groups are tied together with a trajectory id. 
All signalgroups include signals for E2E protection using profile 5 according to Autosar 4.2.2.

Signal group 4 includes:
* 6 PSS points, with overall sequence 21-26
 Delta Y position 2";
CM_ SG_ 286 AdSecPSSGroupSafe4DeltaYPos3 "Platform Safe Stop buffer paths. 

All signalgroups cover 50 points + 1 initial point. Each point has delta X, Y, time and heading. All signal groups are tied together with a trajectory id. 
All signalgroups include signals for E2E protection using profile 5 according to Autosar 4.2.2.

Signal group 4 includes:
* 6 PSS points, with overall sequence 21-26
 Delta Y position 3";
CM_ SG_ 286 AdSecPSSGroupSafe4DeltaYPos4 "Platform Safe Stop buffer paths. 

All signalgroups cover 50 points + 1 initial point. Each point has delta X, Y, time and heading. All signal groups are tied together with a trajectory id. 
All signalgroups include signals for E2E protection using profile 5 according to Autosar 4.2.2.

Signal group 4 includes:
* 6 PSS points, with overall sequence 21-26
 Delta Y position 4";
CM_ SG_ 286 AdSecPSSGroupSafe4DeltaYPos5 "Platform Safe Stop buffer paths. 

All signalgroups cover 50 points + 1 initial point. Each point has delta X, Y, time and heading. All signal groups are tied together with a trajectory id. 
All signalgroups include signals for E2E protection using profile 5 according to Autosar 4.2.2.

Signal group 4 includes:
* 6 PSS points, with overall sequence 21-26
 Delta Y position 5";
CM_ SG_ 286 AdSecPSSGroupSafe4DeltaYPos6 "Platform Safe Stop buffer paths. 

All signalgroups cover 50 points + 1 initial point. Each point has delta X, Y, time and heading. All signal groups are tied together with a trajectory id. 
All signalgroups include signals for E2E protection using profile 5 according to Autosar 4.2.2.

Signal group 4 includes:
* 6 PSS points, with overall sequence 21-26
 Delta Y position 6";
CM_ SG_ 286 AdSecPSSGroupSafe4HeadingPos1 "Platform Safe Stop buffer paths. 

All signalgroups cover 50 points + 1 initial point. Each point has delta X, Y, time and heading. All signal groups are tied together with a trajectory id. 
All signalgroups include signals for E2E protection using profile 5 according to Autosar 4.2.2.

Signal group 4 includes:
* 6 PSS points, with overall sequence 21-26
 Heading position 1";
CM_ SG_ 286 AdSecPSSGroupSafe4HeadingPos2 "Platform Safe Stop buffer paths. 

All signalgroups cover 50 points + 1 initial point. Each point has delta X, Y, time and heading. All signal groups are tied together with a trajectory id. 
All signalgroups include signals for E2E protection using profile 5 according to Autosar 4.2.2.

Signal group 4 includes:
* 6 PSS points, with overall sequence 21-26
 Heading position 2";
CM_ SG_ 286 AdSecPSSGroupSafe4HeadingPos3 "Platform Safe Stop buffer paths. 

All signalgroups cover 50 points + 1 initial point. Each point has delta X, Y, time and heading. All signal groups are tied together with a trajectory id. 
All signalgroups include signals for E2E protection using profile 5 according to Autosar 4.2.2.

Signal group 4 includes:
* 6 PSS points, with overall sequence 21-26
 Heading position 3";
CM_ SG_ 286 AdSecPSSGroupSafe4HeadingPos4 "Platform Safe Stop buffer paths. 

All signalgroups cover 50 points + 1 initial point. Each point has delta X, Y, time and heading. All signal groups are tied together with a trajectory id. 
All signalgroups include signals for E2E protection using profile 5 according to Autosar 4.2.2.

Signal group 4 includes:
* 6 PSS points, with overall sequence 21-26
 Heading position 4";
CM_ SG_ 286 AdSecPSSGroupSafe4HeadingPos5 "Platform Safe Stop buffer paths. 

All signalgroups cover 50 points + 1 initial point. Each point has delta X, Y, time and heading. All signal groups are tied together with a trajectory id. 
All signalgroups include signals for E2E protection using profile 5 according to Autosar 4.2.2.

Signal group 4 includes:
* 6 PSS points, with overall sequence 21-26
 Heading position 5";
CM_ SG_ 286 AdSecPSSGroupSafe4HeadingPos6 "Platform Safe Stop buffer paths. 

All signalgroups cover 50 points + 1 initial point. Each point has delta X, Y, time and heading. All signal groups are tied together with a trajectory id. 
All signalgroups include signals for E2E protection using profile 5 according to Autosar 4.2.2.

Signal group 4 includes:
* 6 PSS points, with overall sequence 21-26
 Heading position 6";
CM_ SG_ 286 AdSecPSSGroupSafe4TrajectID "Platform Safe Stop buffer paths. 

All signalgroups cover 50 points + 1 initial point. Each point has delta X, Y, time and heading. All signal groups are tied together with a trajectory id. 
All signalgroups include signals for E2E protection using profile 5 according to Autosar 4.2.2.

Signal group 4 includes:
* 6 PSS points, with overall sequence 21-26
 Trajectory ID";
CM_ SG_ 289 AdSecPSSGroupSafe5Chks "Platform Safe Stop buffer paths. 

All signalgroups cover 50 points + 1 initial point. Each point has delta X, Y, time and heading. All signal groups are tied together with a trajectory id. 
All signalgroups include signals for E2E protection using profile 5 according to Autosar 4.2.2.

Signal group 5 includes:
* 6 PSS points, with overall sequence 27-32
 E2E checksum, profile 5";
CM_ SG_ 289 AdSecPSSGroupSafe5Cntr "Platform Safe Stop buffer paths. 

All signalgroups cover 50 points + 1 initial point. Each point has delta X, Y, time and heading. All signal groups are tied together with a trajectory id. 
All signalgroups include signals for E2E protection using profile 5 according to Autosar 4.2.2.

Signal group 5 includes:
* 6 PSS points, with overall sequence 27-32
 E2E counter, profile 5";
CM_ SG_ 289 AdSecPSSGroupSafe5DataID "Platform Safe Stop buffer paths. 

All signalgroups cover 50 points + 1 initial point. Each point has delta X, Y, time and heading. All signal groups are tied together with a trajectory id. 
All signalgroups include signals for E2E protection using profile 5 according to Autosar 4.2.2.

Signal group 5 includes:
* 6 PSS points, with overall sequence 27-32
 E2E Data ID, profile 5";
CM_ SG_ 289 AdSecPSSGroupSafe5DeltaTPos1 "Platform Safe Stop buffer paths. 

All signalgroups cover 50 points + 1 initial point. Each point has delta X, Y, time and heading. All signal groups are tied together with a trajectory id. 
All signalgroups include signals for E2E protection using profile 5 according to Autosar 4.2.2.

Signal group 5 includes:
* 6 PSS points, with overall sequence 27-32
 Delta time position 1";
CM_ SG_ 289 AdSecPSSGroupSafe5DeltaTPos2 "Platform Safe Stop buffer paths. 

All signalgroups cover 50 points + 1 initial point. Each point has delta X, Y, time and heading. All signal groups are tied together with a trajectory id. 
All signalgroups include signals for E2E protection using profile 5 according to Autosar 4.2.2.

Signal group 5 includes:
* 6 PSS points, with overall sequence 27-32
 Delta time position 2";
CM_ SG_ 289 AdSecPSSGroupSafe5DeltaTPos3 "Platform Safe Stop buffer paths. 

All signalgroups cover 50 points + 1 initial point. Each point has delta X, Y, time and heading. All signal groups are tied together with a trajectory id. 
All signalgroups include signals for E2E protection using profile 5 according to Autosar 4.2.2.

Signal group 5 includes:
* 6 PSS points, with overall sequence 27-32
 Delta time position 3";
CM_ SG_ 289 AdSecPSSGroupSafe5DeltaTPos4 "Platform Safe Stop buffer paths. 

All signalgroups cover 50 points + 1 initial point. Each point has delta X, Y, time and heading. All signal groups are tied together with a trajectory id. 
All signalgroups include signals for E2E protection using profile 5 according to Autosar 4.2.2.

Signal group 5 includes:
* 6 PSS points, with overall sequence 27-32
 Delta time position 4";
CM_ SG_ 289 AdSecPSSGroupSafe5DeltaTPos5 "Platform Safe Stop buffer paths. 

All signalgroups cover 50 points + 1 initial point. Each point has delta X, Y, time and heading. All signal groups are tied together with a trajectory id. 
All signalgroups include signals for E2E protection using profile 5 according to Autosar 4.2.2.

Signal group 5 includes:
* 6 PSS points, with overall sequence 27-32
 Delta time position 5";
CM_ SG_ 289 AdSecPSSGroupSafe5DeltaTPos6 "Platform Safe Stop buffer paths. 

All signalgroups cover 50 points + 1 initial point. Each point has delta X, Y, time and heading. All signal groups are tied together with a trajectory id. 
All signalgroups include signals for E2E protection using profile 5 according to Autosar 4.2.2.

Signal group 5 includes:
* 6 PSS points, with overall sequence 27-32
 Delta time position 6";
CM_ SG_ 289 AdSecPSSGroupSafe5DeltaXPos1 "Platform Safe Stop buffer paths. 

All signalgroups cover 50 points + 1 initial point. Each point has delta X, Y, time and heading. All signal groups are tied together with a trajectory id. 
All signalgroups include signals for E2E protection using profile 5 according to Autosar 4.2.2.

Signal group 5 includes:
* 6 PSS points, with overall sequence 27-32
 Delta X position 1";
CM_ SG_ 289 AdSecPSSGroupSafe5DeltaXPos2 "Platform Safe Stop buffer paths. 

All signalgroups cover 50 points + 1 initial point. Each point has delta X, Y, time and heading. All signal groups are tied together with a trajectory id. 
All signalgroups include signals for E2E protection using profile 5 according to Autosar 4.2.2.

Signal group 5 includes:
* 6 PSS points, with overall sequence 27-32
 Delta X position 2";
CM_ SG_ 289 AdSecPSSGroupSafe5DeltaXPos3 "Platform Safe Stop buffer paths. 

All signalgroups cover 50 points + 1 initial point. Each point has delta X, Y, time and heading. All signal groups are tied together with a trajectory id. 
All signalgroups include signals for E2E protection using profile 5 according to Autosar 4.2.2.

Signal group 5 includes:
* 6 PSS points, with overall sequence 27-32
 Delta X position 3";
CM_ SG_ 289 AdSecPSSGroupSafe5DeltaXPos4 "Platform Safe Stop buffer paths. 

All signalgroups cover 50 points + 1 initial point. Each point has delta X, Y, time and heading. All signal groups are tied together with a trajectory id. 
All signalgroups include signals for E2E protection using profile 5 according to Autosar 4.2.2.

Signal group 5 includes:
* 6 PSS points, with overall sequence 27-32
 Delta X position 4";
CM_ SG_ 289 AdSecPSSGroupSafe5DeltaXPos5 "Platform Safe Stop buffer paths. 

All signalgroups cover 50 points + 1 initial point. Each point has delta X, Y, time and heading. All signal groups are tied together with a trajectory id. 
All signalgroups include signals for E2E protection using profile 5 according to Autosar 4.2.2.

Signal group 5 includes:
* 6 PSS points, with overall sequence 27-32
 Delta X position 5";
CM_ SG_ 289 AdSecPSSGroupSafe5DeltaXPos6 "Platform Safe Stop buffer paths. 

All signalgroups cover 50 points + 1 initial point. Each point has delta X, Y, time and heading. All signal groups are tied together with a trajectory id. 
All signalgroups include signals for E2E protection using profile 5 according to Autosar 4.2.2.

Signal group 5 includes:
* 6 PSS points, with overall sequence 27-32
 Delta X position 6";
CM_ SG_ 289 AdSecPSSGroupSafe5DeltaYPos1 "Platform Safe Stop buffer paths. 

All signalgroups cover 50 points + 1 initial point. Each point has delta X, Y, time and heading. All signal groups are tied together with a trajectory id. 
All signalgroups include signals for E2E protection using profile 5 according to Autosar 4.2.2.

Signal group 5 includes:
* 6 PSS points, with overall sequence 27-32
 Delta Y position 1";
CM_ SG_ 289 AdSecPSSGroupSafe5DeltaYPos2 "Platform Safe Stop buffer paths. 

All signalgroups cover 50 points + 1 initial point. Each point has delta X, Y, time and heading. All signal groups are tied together with a trajectory id. 
All signalgroups include signals for E2E protection using profile 5 according to Autosar 4.2.2.

Signal group 5 includes:
* 6 PSS points, with overall sequence 27-32
 Delta Y position 2";
CM_ SG_ 289 AdSecPSSGroupSafe5DeltaYPos3 "Platform Safe Stop buffer paths. 

All signalgroups cover 50 points + 1 initial point. Each point has delta X, Y, time and heading. All signal groups are tied together with a trajectory id. 
All signalgroups include signals for E2E protection using profile 5 according to Autosar 4.2.2.

Signal group 5 includes:
* 6 PSS points, with overall sequence 27-32
 Delta Y position 3";
CM_ SG_ 289 AdSecPSSGroupSafe5DeltaYPos4 "Platform Safe Stop buffer paths. 

All signalgroups cover 50 points + 1 initial point. Each point has delta X, Y, time and heading. All signal groups are tied together with a trajectory id. 
All signalgroups include signals for E2E protection using profile 5 according to Autosar 4.2.2.

Signal group 5 includes:
* 6 PSS points, with overall sequence 27-32
 Delta Y position 4";
CM_ SG_ 289 AdSecPSSGroupSafe5DeltaYPos5 "Platform Safe Stop buffer paths. 

All signalgroups cover 50 points + 1 initial point. Each point has delta X, Y, time and heading. All signal groups are tied together with a trajectory id. 
All signalgroups include signals for E2E protection using profile 5 according to Autosar 4.2.2.

Signal group 5 includes:
* 6 PSS points, with overall sequence 27-32
 Delta Y position 5";
CM_ SG_ 289 AdSecPSSGroupSafe5DeltaYPos6 "Platform Safe Stop buffer paths. 

All signalgroups cover 50 points + 1 initial point. Each point has delta X, Y, time and heading. All signal groups are tied together with a trajectory id. 
All signalgroups include signals for E2E protection using profile 5 according to Autosar 4.2.2.

Signal group 5 includes:
* 6 PSS points, with overall sequence 27-32
 Delta Y position 6";
CM_ SG_ 289 AdSecPSSGroupSafe5HeadingPos1 "Platform Safe Stop buffer paths. 

All signalgroups cover 50 points + 1 initial point. Each point has delta X, Y, time and heading. All signal groups are tied together with a trajectory id. 
All signalgroups include signals for E2E protection using profile 5 according to Autosar 4.2.2.

Signal group 5 includes:
* 6 PSS points, with overall sequence 27-32
 Heading position 1";
CM_ SG_ 289 AdSecPSSGroupSafe5HeadingPos2 "Platform Safe Stop buffer paths. 

All signalgroups cover 50 points + 1 initial point. Each point has delta X, Y, time and heading. All signal groups are tied together with a trajectory id. 
All signalgroups include signals for E2E protection using profile 5 according to Autosar 4.2.2.

Signal group 5 includes:
* 6 PSS points, with overall sequence 27-32
 Heading position 2";
CM_ SG_ 289 AdSecPSSGroupSafe5HeadingPos3 "Platform Safe Stop buffer paths. 

All signalgroups cover 50 points + 1 initial point. Each point has delta X, Y, time and heading. All signal groups are tied together with a trajectory id. 
All signalgroups include signals for E2E protection using profile 5 according to Autosar 4.2.2.

Signal group 5 includes:
* 6 PSS points, with overall sequence 27-32
 Heading position 3";
CM_ SG_ 289 AdSecPSSGroupSafe5HeadingPos4 "Platform Safe Stop buffer paths. 

All signalgroups cover 50 points + 1 initial point. Each point has delta X, Y, time and heading. All signal groups are tied together with a trajectory id. 
All signalgroups include signals for E2E protection using profile 5 according to Autosar 4.2.2.

Signal group 5 includes:
* 6 PSS points, with overall sequence 27-32
 Heading position 4";
CM_ SG_ 289 AdSecPSSGroupSafe5HeadingPos5 "Platform Safe Stop buffer paths. 

All signalgroups cover 50 points + 1 initial point. Each point has delta X, Y, time and heading. All signal groups are tied together with a trajectory id. 
All signalgroups include signals for E2E protection using profile 5 according to Autosar 4.2.2.

Signal group 5 includes:
* 6 PSS points, with overall sequence 27-32
 Heading position 5";
CM_ SG_ 289 AdSecPSSGroupSafe5HeadingPos6 "Platform Safe Stop buffer paths. 

All signalgroups cover 50 points + 1 initial point. Each point has delta X, Y, time and heading. All signal groups are tied together with a trajectory id. 
All signalgroups include signals for E2E protection using profile 5 according to Autosar 4.2.2.

Signal group 5 includes:
* 6 PSS points, with overall sequence 27-32
 Heading position 6";
CM_ SG_ 289 AdSecPSSGroupSafe5TrajectID "Platform Safe Stop buffer paths. 

All signalgroups cover 50 points + 1 initial point. Each point has delta X, Y, time and heading. All signal groups are tied together with a trajectory id. 
All signalgroups include signals for E2E protection using profile 5 according to Autosar 4.2.2.

Signal group 5 includes:
* 6 PSS points, with overall sequence 27-32
 Trajectory ID";
CM_ SG_ 292 AdSecPSSGroupSafe6Chks "Platform Safe Stop buffer paths. 

All signalgroups cover 50 points + 1 initial point. Each point has delta X, Y, time and heading. All signal groups are tied together with a trajectory id. 
All signalgroups include signals for E2E protection using profile 5 according to Autosar 4.2.2.

Signal group 6 includes:
* 6 PSS points, with overall sequence 33-38

 E2E checksum, profile 5";
CM_ SG_ 292 AdSecPSSGroupSafe6Cntr "Platform Safe Stop buffer paths. 

All signalgroups cover 50 points + 1 initial point. Each point has delta X, Y, time and heading. All signal groups are tied together with a trajectory id. 
All signalgroups include signals for E2E protection using profile 5 according to Autosar 4.2.2.

Signal group 6 includes:
* 6 PSS points, with overall sequence 33-38

 E2E counter, profile 5";
CM_ SG_ 292 AdSecPSSGroupSafe6DataID "Platform Safe Stop buffer paths. 

All signalgroups cover 50 points + 1 initial point. Each point has delta X, Y, time and heading. All signal groups are tied together with a trajectory id. 
All signalgroups include signals for E2E protection using profile 5 according to Autosar 4.2.2.

Signal group 6 includes:
* 6 PSS points, with overall sequence 33-38

 E2E Data ID, profile 5";
CM_ SG_ 292 AdSecPSSGroupSafe6DeltaTPos1 "Platform Safe Stop buffer paths. 

All signalgroups cover 50 points + 1 initial point. Each point has delta X, Y, time and heading. All signal groups are tied together with a trajectory id. 
All signalgroups include signals for E2E protection using profile 5 according to Autosar 4.2.2.

Signal group 6 includes:
* 6 PSS points, with overall sequence 33-38

 Delta time position 1";
CM_ SG_ 292 AdSecPSSGroupSafe6DeltaTPos2 "Platform Safe Stop buffer paths. 

All signalgroups cover 50 points + 1 initial point. Each point has delta X, Y, time and heading. All signal groups are tied together with a trajectory id. 
All signalgroups include signals for E2E protection using profile 5 according to Autosar 4.2.2.

Signal group 6 includes:
* 6 PSS points, with overall sequence 33-38

 Delta time position 2";
CM_ SG_ 292 AdSecPSSGroupSafe6DeltaTPos3 "Platform Safe Stop buffer paths. 

All signalgroups cover 50 points + 1 initial point. Each point has delta X, Y, time and heading. All signal groups are tied together with a trajectory id. 
All signalgroups include signals for E2E protection using profile 5 according to Autosar 4.2.2.

Signal group 6 includes:
* 6 PSS points, with overall sequence 33-38

 Delta time position 3";
CM_ SG_ 292 AdSecPSSGroupSafe6DeltaTPos4 "Platform Safe Stop buffer paths. 

All signalgroups cover 50 points + 1 initial point. Each point has delta X, Y, time and heading. All signal groups are tied together with a trajectory id. 
All signalgroups include signals for E2E protection using profile 5 according to Autosar 4.2.2.

Signal group 6 includes:
* 6 PSS points, with overall sequence 33-38

 Delta time position 4";
CM_ SG_ 292 AdSecPSSGroupSafe6DeltaTPos5 "Platform Safe Stop buffer paths. 

All signalgroups cover 50 points + 1 initial point. Each point has delta X, Y, time and heading. All signal groups are tied together with a trajectory id. 
All signalgroups include signals for E2E protection using profile 5 according to Autosar 4.2.2.

Signal group 6 includes:
* 6 PSS points, with overall sequence 33-38

 Delta time position 5";
CM_ SG_ 292 AdSecPSSGroupSafe6DeltaTPos6 "Platform Safe Stop buffer paths. 

All signalgroups cover 50 points + 1 initial point. Each point has delta X, Y, time and heading. All signal groups are tied together with a trajectory id. 
All signalgroups include signals for E2E protection using profile 5 according to Autosar 4.2.2.

Signal group 6 includes:
* 6 PSS points, with overall sequence 33-38

 Delta time position 6";
CM_ SG_ 292 AdSecPSSGroupSafe6DeltaXPos1 "Platform Safe Stop buffer paths. 

All signalgroups cover 50 points + 1 initial point. Each point has delta X, Y, time and heading. All signal groups are tied together with a trajectory id. 
All signalgroups include signals for E2E protection using profile 5 according to Autosar 4.2.2.

Signal group 6 includes:
* 6 PSS points, with overall sequence 33-38

 Delta X position 1";
CM_ SG_ 292 AdSecPSSGroupSafe6DeltaXPos2 "Platform Safe Stop buffer paths. 

All signalgroups cover 50 points + 1 initial point. Each point has delta X, Y, time and heading. All signal groups are tied together with a trajectory id. 
All signalgroups include signals for E2E protection using profile 5 according to Autosar 4.2.2.

Signal group 6 includes:
* 6 PSS points, with overall sequence 33-38

 Delta X position 2";
CM_ SG_ 292 AdSecPSSGroupSafe6DeltaXPos3 "Platform Safe Stop buffer paths. 

All signalgroups cover 50 points + 1 initial point. Each point has delta X, Y, time and heading. All signal groups are tied together with a trajectory id. 
All signalgroups include signals for E2E protection using profile 5 according to Autosar 4.2.2.

Signal group 6 includes:
* 6 PSS points, with overall sequence 33-38

 Delta X position 3";
CM_ SG_ 292 AdSecPSSGroupSafe6DeltaXPos4 "Platform Safe Stop buffer paths. 

All signalgroups cover 50 points + 1 initial point. Each point has delta X, Y, time and heading. All signal groups are tied together with a trajectory id. 
All signalgroups include signals for E2E protection using profile 5 according to Autosar 4.2.2.

Signal group 6 includes:
* 6 PSS points, with overall sequence 33-38

 Delta X position 4";
CM_ SG_ 292 AdSecPSSGroupSafe6DeltaXPos5 "Platform Safe Stop buffer paths. 

All signalgroups cover 50 points + 1 initial point. Each point has delta X, Y, time and heading. All signal groups are tied together with a trajectory id. 
All signalgroups include signals for E2E protection using profile 5 according to Autosar 4.2.2.

Signal group 6 includes:
* 6 PSS points, with overall sequence 33-38

 Delta X position 5";
CM_ SG_ 292 AdSecPSSGroupSafe6DeltaXPos6 "Platform Safe Stop buffer paths. 

All signalgroups cover 50 points + 1 initial point. Each point has delta X, Y, time and heading. All signal groups are tied together with a trajectory id. 
All signalgroups include signals for E2E protection using profile 5 according to Autosar 4.2.2.

Signal group 6 includes:
* 6 PSS points, with overall sequence 33-38

 Delta X position 6";
CM_ SG_ 292 AdSecPSSGroupSafe6DeltaYPos1 "Platform Safe Stop buffer paths. 

All signalgroups cover 50 points + 1 initial point. Each point has delta X, Y, time and heading. All signal groups are tied together with a trajectory id. 
All signalgroups include signals for E2E protection using profile 5 according to Autosar 4.2.2.

Signal group 6 includes:
* 6 PSS points, with overall sequence 33-38

 Delta Y position 1";
CM_ SG_ 292 AdSecPSSGroupSafe6DeltaYPos2 "Platform Safe Stop buffer paths. 

All signalgroups cover 50 points + 1 initial point. Each point has delta X, Y, time and heading. All signal groups are tied together with a trajectory id. 
All signalgroups include signals for E2E protection using profile 5 according to Autosar 4.2.2.

Signal group 6 includes:
* 6 PSS points, with overall sequence 33-38

 Delta Y position 2";
CM_ SG_ 292 AdSecPSSGroupSafe6DeltaYPos3 "Platform Safe Stop buffer paths. 

All signalgroups cover 50 points + 1 initial point. Each point has delta X, Y, time and heading. All signal groups are tied together with a trajectory id. 
All signalgroups include signals for E2E protection using profile 5 according to Autosar 4.2.2.

Signal group 6 includes:
* 6 PSS points, with overall sequence 33-38

 Delta Y position 3";
CM_ SG_ 292 AdSecPSSGroupSafe6DeltaYPos4 "Platform Safe Stop buffer paths. 

All signalgroups cover 50 points + 1 initial point. Each point has delta X, Y, time and heading. All signal groups are tied together with a trajectory id. 
All signalgroups include signals for E2E protection using profile 5 according to Autosar 4.2.2.

Signal group 6 includes:
* 6 PSS points, with overall sequence 33-38

 Delta Y position 4";
CM_ SG_ 292 AdSecPSSGroupSafe6DeltaYPos5 "Platform Safe Stop buffer paths. 

All signalgroups cover 50 points + 1 initial point. Each point has delta X, Y, time and heading. All signal groups are tied together with a trajectory id. 
All signalgroups include signals for E2E protection using profile 5 according to Autosar 4.2.2.

Signal group 6 includes:
* 6 PSS points, with overall sequence 33-38

 Delta Y position 5";
CM_ SG_ 292 AdSecPSSGroupSafe6DeltaYPos6 "Platform Safe Stop buffer paths. 

All signalgroups cover 50 points + 1 initial point. Each point has delta X, Y, time and heading. All signal groups are tied together with a trajectory id. 
All signalgroups include signals for E2E protection using profile 5 according to Autosar 4.2.2.

Signal group 6 includes:
* 6 PSS points, with overall sequence 33-38

 Delta Y position 6";
CM_ SG_ 292 AdSecPSSGroupSafe6HeadingPos1 "Platform Safe Stop buffer paths. 

All signalgroups cover 50 points + 1 initial point. Each point has delta X, Y, time and heading. All signal groups are tied together with a trajectory id. 
All signalgroups include signals for E2E protection using profile 5 according to Autosar 4.2.2.

Signal group 6 includes:
* 6 PSS points, with overall sequence 33-38

 Heading position 1";
CM_ SG_ 292 AdSecPSSGroupSafe6HeadingPos2 "Platform Safe Stop buffer paths. 

All signalgroups cover 50 points + 1 initial point. Each point has delta X, Y, time and heading. All signal groups are tied together with a trajectory id. 
All signalgroups include signals for E2E protection using profile 5 according to Autosar 4.2.2.

Signal group 6 includes:
* 6 PSS points, with overall sequence 33-38

 Heading position 2";
CM_ SG_ 292 AdSecPSSGroupSafe6HeadingPos3 "Platform Safe Stop buffer paths. 

All signalgroups cover 50 points + 1 initial point. Each point has delta X, Y, time and heading. All signal groups are tied together with a trajectory id. 
All signalgroups include signals for E2E protection using profile 5 according to Autosar 4.2.2.

Signal group 6 includes:
* 6 PSS points, with overall sequence 33-38

 Heading position 3";
CM_ SG_ 292 AdSecPSSGroupSafe6HeadingPos4 "Platform Safe Stop buffer paths. 

All signalgroups cover 50 points + 1 initial point. Each point has delta X, Y, time and heading. All signal groups are tied together with a trajectory id. 
All signalgroups include signals for E2E protection using profile 5 according to Autosar 4.2.2.

Signal group 6 includes:
* 6 PSS points, with overall sequence 33-38

 Heading position 4";
CM_ SG_ 292 AdSecPSSGroupSafe6HeadingPos5 "Platform Safe Stop buffer paths. 

All signalgroups cover 50 points + 1 initial point. Each point has delta X, Y, time and heading. All signal groups are tied together with a trajectory id. 
All signalgroups include signals for E2E protection using profile 5 according to Autosar 4.2.2.

Signal group 6 includes:
* 6 PSS points, with overall sequence 33-38

 Heading position 5";
CM_ SG_ 292 AdSecPSSGroupSafe6HeadingPos6 "Platform Safe Stop buffer paths. 

All signalgroups cover 50 points + 1 initial point. Each point has delta X, Y, time and heading. All signal groups are tied together with a trajectory id. 
All signalgroups include signals for E2E protection using profile 5 according to Autosar 4.2.2.

Signal group 6 includes:
* 6 PSS points, with overall sequence 33-38

 Heading position 6";
CM_ SG_ 292 AdSecPSSGroupSafe6TrajectID "Platform Safe Stop buffer paths. 

All signalgroups cover 50 points + 1 initial point. Each point has delta X, Y, time and heading. All signal groups are tied together with a trajectory id. 
All signalgroups include signals for E2E protection using profile 5 according to Autosar 4.2.2.

Signal group 6 includes:
* 6 PSS points, with overall sequence 33-38

 Trajectory ID";
CM_ SG_ 295 AdSecPSSGroupSafe7Chks "Platform Safe Stop buffer paths. 

All signalgroups cover 50 points + 1 initial point. Each point has delta X, Y, time and heading. All signal groups are tied together with a trajectory id. 
All signalgroups include signals for E2E protection using profile 5 according to Autosar 4.2.2.

Signal group 7 includes:
* 6 PSS points, with overall sequence 39-44 E2E checksum, profile 5";
CM_ SG_ 295 AdSecPSSGroupSafe7Cntr "Platform Safe Stop buffer paths. 

All signalgroups cover 50 points + 1 initial point. Each point has delta X, Y, time and heading. All signal groups are tied together with a trajectory id. 
All signalgroups include signals for E2E protection using profile 5 according to Autosar 4.2.2.

Signal group 7 includes:
* 6 PSS points, with overall sequence 39-44 E2E counter, profile 5";
CM_ SG_ 295 AdSecPSSGroupSafe7DataID "Platform Safe Stop buffer paths. 

All signalgroups cover 50 points + 1 initial point. Each point has delta X, Y, time and heading. All signal groups are tied together with a trajectory id. 
All signalgroups include signals for E2E protection using profile 5 according to Autosar 4.2.2.

Signal group 7 includes:
* 6 PSS points, with overall sequence 39-44 E2E Data ID, profile 5";
CM_ SG_ 295 AdSecPSSGroupSafe7DeltaTPos1 "Platform Safe Stop buffer paths. 

All signalgroups cover 50 points + 1 initial point. Each point has delta X, Y, time and heading. All signal groups are tied together with a trajectory id. 
All signalgroups include signals for E2E protection using profile 5 according to Autosar 4.2.2.

Signal group 7 includes:
* 6 PSS points, with overall sequence 39-44 Delta time position 1";
CM_ SG_ 295 AdSecPSSGroupSafe7DeltaTPos2 "Platform Safe Stop buffer paths. 

All signalgroups cover 50 points + 1 initial point. Each point has delta X, Y, time and heading. All signal groups are tied together with a trajectory id. 
All signalgroups include signals for E2E protection using profile 5 according to Autosar 4.2.2.

Signal group 7 includes:
* 6 PSS points, with overall sequence 39-44 Delta time position 2";
CM_ SG_ 295 AdSecPSSGroupSafe7DeltaTPos3 "Platform Safe Stop buffer paths. 

All signalgroups cover 50 points + 1 initial point. Each point has delta X, Y, time and heading. All signal groups are tied together with a trajectory id. 
All signalgroups include signals for E2E protection using profile 5 according to Autosar 4.2.2.

Signal group 7 includes:
* 6 PSS points, with overall sequence 39-44 Delta time position 3";
CM_ SG_ 295 AdSecPSSGroupSafe7DeltaTPos4 "Platform Safe Stop buffer paths. 

All signalgroups cover 50 points + 1 initial point. Each point has delta X, Y, time and heading. All signal groups are tied together with a trajectory id. 
All signalgroups include signals for E2E protection using profile 5 according to Autosar 4.2.2.

Signal group 7 includes:
* 6 PSS points, with overall sequence 39-44 Delta time position 4";
CM_ SG_ 295 AdSecPSSGroupSafe7DeltaTPos5 "Platform Safe Stop buffer paths. 

All signalgroups cover 50 points + 1 initial point. Each point has delta X, Y, time and heading. All signal groups are tied together with a trajectory id. 
All signalgroups include signals for E2E protection using profile 5 according to Autosar 4.2.2.

Signal group 7 includes:
* 6 PSS points, with overall sequence 39-44 Delta time position 5";
CM_ SG_ 295 AdSecPSSGroupSafe7DeltaTPos6 "Platform Safe Stop buffer paths. 

All signalgroups cover 50 points + 1 initial point. Each point has delta X, Y, time and heading. All signal groups are tied together with a trajectory id. 
All signalgroups include signals for E2E protection using profile 5 according to Autosar 4.2.2.

Signal group 7 includes:
* 6 PSS points, with overall sequence 39-44 Delta time position 6";
CM_ SG_ 295 AdSecPSSGroupSafe7DeltaXPos1 "Platform Safe Stop buffer paths. 

All signalgroups cover 50 points + 1 initial point. Each point has delta X, Y, time and heading. All signal groups are tied together with a trajectory id. 
All signalgroups include signals for E2E protection using profile 5 according to Autosar 4.2.2.

Signal group 7 includes:
* 6 PSS points, with overall sequence 39-44 Delta X position 1";
CM_ SG_ 295 AdSecPSSGroupSafe7DeltaXPos2 "Platform Safe Stop buffer paths. 

All signalgroups cover 50 points + 1 initial point. Each point has delta X, Y, time and heading. All signal groups are tied together with a trajectory id. 
All signalgroups include signals for E2E protection using profile 5 according to Autosar 4.2.2.

Signal group 7 includes:
* 6 PSS points, with overall sequence 39-44 Delta X position 2";
CM_ SG_ 295 AdSecPSSGroupSafe7DeltaXPos3 "Platform Safe Stop buffer paths. 

All signalgroups cover 50 points + 1 initial point. Each point has delta X, Y, time and heading. All signal groups are tied together with a trajectory id. 
All signalgroups include signals for E2E protection using profile 5 according to Autosar 4.2.2.

Signal group 7 includes:
* 6 PSS points, with overall sequence 39-44 Delta X position 3";
CM_ SG_ 295 AdSecPSSGroupSafe7DeltaXPos4 "Platform Safe Stop buffer paths. 

All signalgroups cover 50 points + 1 initial point. Each point has delta X, Y, time and heading. All signal groups are tied together with a trajectory id. 
All signalgroups include signals for E2E protection using profile 5 according to Autosar 4.2.2.

Signal group 7 includes:
* 6 PSS points, with overall sequence 39-44 Delta X position 4";
CM_ SG_ 295 AdSecPSSGroupSafe7DeltaXPos5 "Platform Safe Stop buffer paths. 

All signalgroups cover 50 points + 1 initial point. Each point has delta X, Y, time and heading. All signal groups are tied together with a trajectory id. 
All signalgroups include signals for E2E protection using profile 5 according to Autosar 4.2.2.

Signal group 7 includes:
* 6 PSS points, with overall sequence 39-44 Delta X position 5";
CM_ SG_ 295 AdSecPSSGroupSafe7DeltaXPos6 "Platform Safe Stop buffer paths. 

All signalgroups cover 50 points + 1 initial point. Each point has delta X, Y, time and heading. All signal groups are tied together with a trajectory id. 
All signalgroups include signals for E2E protection using profile 5 according to Autosar 4.2.2.

Signal group 7 includes:
* 6 PSS points, with overall sequence 39-44 Delta X position 6";
CM_ SG_ 295 AdSecPSSGroupSafe7DeltaYPos1 "Platform Safe Stop buffer paths. 

All signalgroups cover 50 points + 1 initial point. Each point has delta X, Y, time and heading. All signal groups are tied together with a trajectory id. 
All signalgroups include signals for E2E protection using profile 5 according to Autosar 4.2.2.

Signal group 7 includes:
* 6 PSS points, with overall sequence 39-44 Delta Y position 1";
CM_ SG_ 295 AdSecPSSGroupSafe7DeltaYPos2 "Platform Safe Stop buffer paths. 

All signalgroups cover 50 points + 1 initial point. Each point has delta X, Y, time and heading. All signal groups are tied together with a trajectory id. 
All signalgroups include signals for E2E protection using profile 5 according to Autosar 4.2.2.

Signal group 7 includes:
* 6 PSS points, with overall sequence 39-44 Delta Y position 2";
CM_ SG_ 295 AdSecPSSGroupSafe7DeltaYPos3 "Platform Safe Stop buffer paths. 

All signalgroups cover 50 points + 1 initial point. Each point has delta X, Y, time and heading. All signal groups are tied together with a trajectory id. 
All signalgroups include signals for E2E protection using profile 5 according to Autosar 4.2.2.

Signal group 7 includes:
* 6 PSS points, with overall sequence 39-44 Delta Y position 3";
CM_ SG_ 295 AdSecPSSGroupSafe7DeltaYPos4 "Platform Safe Stop buffer paths. 

All signalgroups cover 50 points + 1 initial point. Each point has delta X, Y, time and heading. All signal groups are tied together with a trajectory id. 
All signalgroups include signals for E2E protection using profile 5 according to Autosar 4.2.2.

Signal group 7 includes:
* 6 PSS points, with overall sequence 39-44 Delta Y position 4";
CM_ SG_ 295 AdSecPSSGroupSafe7DeltaYPos5 "Platform Safe Stop buffer paths. 

All signalgroups cover 50 points + 1 initial point. Each point has delta X, Y, time and heading. All signal groups are tied together with a trajectory id. 
All signalgroups include signals for E2E protection using profile 5 according to Autosar 4.2.2.

Signal group 7 includes:
* 6 PSS points, with overall sequence 39-44 Delta Y position 5";
CM_ SG_ 295 AdSecPSSGroupSafe7DeltaYPos6 "Platform Safe Stop buffer paths. 

All signalgroups cover 50 points + 1 initial point. Each point has delta X, Y, time and heading. All signal groups are tied together with a trajectory id. 
All signalgroups include signals for E2E protection using profile 5 according to Autosar 4.2.2.

Signal group 7 includes:
* 6 PSS points, with overall sequence 39-44 Delta Y position 6";
CM_ SG_ 295 AdSecPSSGroupSafe7HeadingPos1 "Platform Safe Stop buffer paths. 

All signalgroups cover 50 points + 1 initial point. Each point has delta X, Y, time and heading. All signal groups are tied together with a trajectory id. 
All signalgroups include signals for E2E protection using profile 5 according to Autosar 4.2.2.

Signal group 7 includes:
* 6 PSS points, with overall sequence 39-44 Heading position 1";
CM_ SG_ 295 AdSecPSSGroupSafe7HeadingPos2 "Platform Safe Stop buffer paths. 

All signalgroups cover 50 points + 1 initial point. Each point has delta X, Y, time and heading. All signal groups are tied together with a trajectory id. 
All signalgroups include signals for E2E protection using profile 5 according to Autosar 4.2.2.

Signal group 7 includes:
* 6 PSS points, with overall sequence 39-44 Heading position 2";
CM_ SG_ 295 AdSecPSSGroupSafe7HeadingPos3 "Platform Safe Stop buffer paths. 

All signalgroups cover 50 points + 1 initial point. Each point has delta X, Y, time and heading. All signal groups are tied together with a trajectory id. 
All signalgroups include signals for E2E protection using profile 5 according to Autosar 4.2.2.

Signal group 7 includes:
* 6 PSS points, with overall sequence 39-44 Heading position 3";
CM_ SG_ 295 AdSecPSSGroupSafe7HeadingPos4 "Platform Safe Stop buffer paths. 

All signalgroups cover 50 points + 1 initial point. Each point has delta X, Y, time and heading. All signal groups are tied together with a trajectory id. 
All signalgroups include signals for E2E protection using profile 5 according to Autosar 4.2.2.

Signal group 7 includes:
* 6 PSS points, with overall sequence 39-44 Heading position 4";
CM_ SG_ 295 AdSecPSSGroupSafe7HeadingPos5 "Platform Safe Stop buffer paths. 

All signalgroups cover 50 points + 1 initial point. Each point has delta X, Y, time and heading. All signal groups are tied together with a trajectory id. 
All signalgroups include signals for E2E protection using profile 5 according to Autosar 4.2.2.

Signal group 7 includes:
* 6 PSS points, with overall sequence 39-44 Heading position 5";
CM_ SG_ 295 AdSecPSSGroupSafe7HeadingPos6 "Platform Safe Stop buffer paths. 

All signalgroups cover 50 points + 1 initial point. Each point has delta X, Y, time and heading. All signal groups are tied together with a trajectory id. 
All signalgroups include signals for E2E protection using profile 5 according to Autosar 4.2.2.

Signal group 7 includes:
* 6 PSS points, with overall sequence 39-44 Heading position 6";
CM_ SG_ 295 AdSecPSSGroupSafe7TrajectID "Platform Safe Stop buffer paths. 

All signalgroups cover 50 points + 1 initial point. Each point has delta X, Y, time and heading. All signal groups are tied together with a trajectory id. 
All signalgroups include signals for E2E protection using profile 5 according to Autosar 4.2.2.

Signal group 7 includes:
* 6 PSS points, with overall sequence 39-44 Trajectory ID";
CM_ SG_ 296 AdSecPSSGroupSafe8Chks "Platform Safe Stop buffer paths. 

All signalgroups cover 50 points + 1 initial point. Each point has delta X, Y, time and heading. All signal groups are tied together with a trajectory id. 
All signalgroups include signals for E2E protection using profile 5 according to Autosar 4.2.2.

Signal group 8 includes:
* 6 PSS points, with overall sequence 45-50 E2E checksum, profile 5";
CM_ SG_ 296 AdSecPSSGroupSafe8Cntr "Platform Safe Stop buffer paths. 

All signalgroups cover 50 points + 1 initial point. Each point has delta X, Y, time and heading. All signal groups are tied together with a trajectory id. 
All signalgroups include signals for E2E protection using profile 5 according to Autosar 4.2.2.

Signal group 8 includes:
* 6 PSS points, with overall sequence 45-50 E2E counter, profile 5";
CM_ SG_ 296 AdSecPSSGroupSafe8DataID "Platform Safe Stop buffer paths. 

All signalgroups cover 50 points + 1 initial point. Each point has delta X, Y, time and heading. All signal groups are tied together with a trajectory id. 
All signalgroups include signals for E2E protection using profile 5 according to Autosar 4.2.2.

Signal group 8 includes:
* 6 PSS points, with overall sequence 45-50 E2E Data ID, profile 5";
CM_ SG_ 296 AdSecPSSGroupSafe8DeltaTPos1 "Platform Safe Stop buffer paths. 

All signalgroups cover 50 points + 1 initial point. Each point has delta X, Y, time and heading. All signal groups are tied together with a trajectory id. 
All signalgroups include signals for E2E protection using profile 5 according to Autosar 4.2.2.

Signal group 8 includes:
* 6 PSS points, with overall sequence 45-50 Delta time position 1";
CM_ SG_ 296 AdSecPSSGroupSafe8DeltaTPos2 "Platform Safe Stop buffer paths. 

All signalgroups cover 50 points + 1 initial point. Each point has delta X, Y, time and heading. All signal groups are tied together with a trajectory id. 
All signalgroups include signals for E2E protection using profile 5 according to Autosar 4.2.2.

Signal group 8 includes:
* 6 PSS points, with overall sequence 45-50 Delta time position 2";
CM_ SG_ 296 AdSecPSSGroupSafe8DeltaTPos3 "Platform Safe Stop buffer paths. 

All signalgroups cover 50 points + 1 initial point. Each point has delta X, Y, time and heading. All signal groups are tied together with a trajectory id. 
All signalgroups include signals for E2E protection using profile 5 according to Autosar 4.2.2.

Signal group 8 includes:
* 6 PSS points, with overall sequence 45-50 Delta time position 3";
CM_ SG_ 296 AdSecPSSGroupSafe8DeltaTPos4 "Platform Safe Stop buffer paths. 

All signalgroups cover 50 points + 1 initial point. Each point has delta X, Y, time and heading. All signal groups are tied together with a trajectory id. 
All signalgroups include signals for E2E protection using profile 5 according to Autosar 4.2.2.

Signal group 8 includes:
* 6 PSS points, with overall sequence 45-50 Delta time position 4";
CM_ SG_ 296 AdSecPSSGroupSafe8DeltaTPos5 "Platform Safe Stop buffer paths. 

All signalgroups cover 50 points + 1 initial point. Each point has delta X, Y, time and heading. All signal groups are tied together with a trajectory id. 
All signalgroups include signals for E2E protection using profile 5 according to Autosar 4.2.2.

Signal group 8 includes:
* 6 PSS points, with overall sequence 45-50 Delta time position 5";
CM_ SG_ 296 AdSecPSSGroupSafe8DeltaTPos6 "Platform Safe Stop buffer paths. 

All signalgroups cover 50 points + 1 initial point. Each point has delta X, Y, time and heading. All signal groups are tied together with a trajectory id. 
All signalgroups include signals for E2E protection using profile 5 according to Autosar 4.2.2.

Signal group 8 includes:
* 6 PSS points, with overall sequence 45-50 Delta time position 6";
CM_ SG_ 296 AdSecPSSGroupSafe8DeltaXPos1 "Platform Safe Stop buffer paths. 

All signalgroups cover 50 points + 1 initial point. Each point has delta X, Y, time and heading. All signal groups are tied together with a trajectory id. 
All signalgroups include signals for E2E protection using profile 5 according to Autosar 4.2.2.

Signal group 8 includes:
* 6 PSS points, with overall sequence 45-50 Delta X position 1";
CM_ SG_ 296 AdSecPSSGroupSafe8DeltaXPos2 "Platform Safe Stop buffer paths. 

All signalgroups cover 50 points + 1 initial point. Each point has delta X, Y, time and heading. All signal groups are tied together with a trajectory id. 
All signalgroups include signals for E2E protection using profile 5 according to Autosar 4.2.2.

Signal group 8 includes:
* 6 PSS points, with overall sequence 45-50 Delta X position 2";
CM_ SG_ 296 AdSecPSSGroupSafe8DeltaXPos3 "Platform Safe Stop buffer paths. 

All signalgroups cover 50 points + 1 initial point. Each point has delta X, Y, time and heading. All signal groups are tied together with a trajectory id. 
All signalgroups include signals for E2E protection using profile 5 according to Autosar 4.2.2.

Signal group 8 includes:
* 6 PSS points, with overall sequence 45-50 Delta X position 3";
CM_ SG_ 296 AdSecPSSGroupSafe8DeltaXPos4 "Platform Safe Stop buffer paths. 

All signalgroups cover 50 points + 1 initial point. Each point has delta X, Y, time and heading. All signal groups are tied together with a trajectory id. 
All signalgroups include signals for E2E protection using profile 5 according to Autosar 4.2.2.

Signal group 8 includes:
* 6 PSS points, with overall sequence 45-50 Delta X position 4";
CM_ SG_ 296 AdSecPSSGroupSafe8DeltaXPos5 "Platform Safe Stop buffer paths. 

All signalgroups cover 50 points + 1 initial point. Each point has delta X, Y, time and heading. All signal groups are tied together with a trajectory id. 
All signalgroups include signals for E2E protection using profile 5 according to Autosar 4.2.2.

Signal group 8 includes:
* 6 PSS points, with overall sequence 45-50 Delta X position 5";
CM_ SG_ 296 AdSecPSSGroupSafe8DeltaXPos6 "Platform Safe Stop buffer paths. 

All signalgroups cover 50 points + 1 initial point. Each point has delta X, Y, time and heading. All signal groups are tied together with a trajectory id. 
All signalgroups include signals for E2E protection using profile 5 according to Autosar 4.2.2.

Signal group 8 includes:
* 6 PSS points, with overall sequence 45-50 Delta X position 6";
CM_ SG_ 296 AdSecPSSGroupSafe8DeltaYPos1 "Platform Safe Stop buffer paths. 

All signalgroups cover 50 points + 1 initial point. Each point has delta X, Y, time and heading. All signal groups are tied together with a trajectory id. 
All signalgroups include signals for E2E protection using profile 5 according to Autosar 4.2.2.

Signal group 8 includes:
* 6 PSS points, with overall sequence 45-50 Delta Y position 1";
CM_ SG_ 296 AdSecPSSGroupSafe8DeltaYPos2 "Platform Safe Stop buffer paths. 

All signalgroups cover 50 points + 1 initial point. Each point has delta X, Y, time and heading. All signal groups are tied together with a trajectory id. 
All signalgroups include signals for E2E protection using profile 5 according to Autosar 4.2.2.

Signal group 8 includes:
* 6 PSS points, with overall sequence 45-50 Delta Y position 2";
CM_ SG_ 296 AdSecPSSGroupSafe8DeltaYPos3 "Platform Safe Stop buffer paths. 

All signalgroups cover 50 points + 1 initial point. Each point has delta X, Y, time and heading. All signal groups are tied together with a trajectory id. 
All signalgroups include signals for E2E protection using profile 5 according to Autosar 4.2.2.

Signal group 8 includes:
* 6 PSS points, with overall sequence 45-50 Delta Y position 3";
CM_ SG_ 296 AdSecPSSGroupSafe8DeltaYPos4 "Platform Safe Stop buffer paths. 

All signalgroups cover 50 points + 1 initial point. Each point has delta X, Y, time and heading. All signal groups are tied together with a trajectory id. 
All signalgroups include signals for E2E protection using profile 5 according to Autosar 4.2.2.

Signal group 8 includes:
* 6 PSS points, with overall sequence 45-50 Delta Y position 4";
CM_ SG_ 296 AdSecPSSGroupSafe8DeltaYPos5 "Platform Safe Stop buffer paths. 

All signalgroups cover 50 points + 1 initial point. Each point has delta X, Y, time and heading. All signal groups are tied together with a trajectory id. 
All signalgroups include signals for E2E protection using profile 5 according to Autosar 4.2.2.

Signal group 8 includes:
* 6 PSS points, with overall sequence 45-50 Delta Y position 5";
CM_ SG_ 296 AdSecPSSGroupSafe8DeltaYPos6 "Platform Safe Stop buffer paths. 

All signalgroups cover 50 points + 1 initial point. Each point has delta X, Y, time and heading. All signal groups are tied together with a trajectory id. 
All signalgroups include signals for E2E protection using profile 5 according to Autosar 4.2.2.

Signal group 8 includes:
* 6 PSS points, with overall sequence 45-50 Delta Y position 6";
CM_ SG_ 296 AdSecPSSGroupSafe8HeadingPos1 "Platform Safe Stop buffer paths. 

All signalgroups cover 50 points + 1 initial point. Each point has delta X, Y, time and heading. All signal groups are tied together with a trajectory id. 
All signalgroups include signals for E2E protection using profile 5 according to Autosar 4.2.2.

Signal group 8 includes:
* 6 PSS points, with overall sequence 45-50 Heading position 1";
CM_ SG_ 296 AdSecPSSGroupSafe8HeadingPos2 "Platform Safe Stop buffer paths. 

All signalgroups cover 50 points + 1 initial point. Each point has delta X, Y, time and heading. All signal groups are tied together with a trajectory id. 
All signalgroups include signals for E2E protection using profile 5 according to Autosar 4.2.2.

Signal group 8 includes:
* 6 PSS points, with overall sequence 45-50 Heading position 2";
CM_ SG_ 296 AdSecPSSGroupSafe8HeadingPos3 "Platform Safe Stop buffer paths. 

All signalgroups cover 50 points + 1 initial point. Each point has delta X, Y, time and heading. All signal groups are tied together with a trajectory id. 
All signalgroups include signals for E2E protection using profile 5 according to Autosar 4.2.2.

Signal group 8 includes:
* 6 PSS points, with overall sequence 45-50 Heading position 3";
CM_ SG_ 296 AdSecPSSGroupSafe8HeadingPos4 "Platform Safe Stop buffer paths. 

All signalgroups cover 50 points + 1 initial point. Each point has delta X, Y, time and heading. All signal groups are tied together with a trajectory id. 
All signalgroups include signals for E2E protection using profile 5 according to Autosar 4.2.2.

Signal group 8 includes:
* 6 PSS points, with overall sequence 45-50 Heading position 4";
CM_ SG_ 296 AdSecPSSGroupSafe8HeadingPos5 "Platform Safe Stop buffer paths. 

All signalgroups cover 50 points + 1 initial point. Each point has delta X, Y, time and heading. All signal groups are tied together with a trajectory id. 
All signalgroups include signals for E2E protection using profile 5 according to Autosar 4.2.2.

Signal group 8 includes:
* 6 PSS points, with overall sequence 45-50 Heading position 5";
CM_ SG_ 296 AdSecPSSGroupSafe8HeadingPos6 "Platform Safe Stop buffer paths. 

All signalgroups cover 50 points + 1 initial point. Each point has delta X, Y, time and heading. All signal groups are tied together with a trajectory id. 
All signalgroups include signals for E2E protection using profile 5 according to Autosar 4.2.2.

Signal group 8 includes:
* 6 PSS points, with overall sequence 45-50 Heading position 6";
CM_ SG_ 296 AdSecPSSGroupSafe8TrajectID "Platform Safe Stop buffer paths. 

All signalgroups cover 50 points + 1 initial point. Each point has delta X, Y, time and heading. All signal groups are tied together with a trajectory id. 
All signalgroups include signals for E2E protection using profile 5 according to Autosar 4.2.2.

Signal group 8 includes:
* 6 PSS points, with overall sequence 45-50 Trajectory ID";
CM_ SG_ 80 AdSecALgtLimReqGroupSafeALgtMaxReq "Safety critical acceleration request from HAD. Safety critical acceleration request from HAD.";
CM_ SG_ 80 AdSecALgtLimReqGroupSafeALgtMinReq "Safety critical acceleration request from HAD. Safety critical acceleration request from HAD.";
CM_ SG_ 80 AdSecALgtLimReqGroupSafeChks "Safety critical acceleration request from HAD. E2E checksum";
CM_ SG_ 80 AdSecALgtLimReqGroupSafeCntr "Safety critical acceleration request from HAD. E2E Counter";
CM_ SG_ 80 SecAdNomALgtReqGroupSafeALgtNomReqMax "Secondary nominal longitudinal acceleration request Nominal acceleration req from HAD.";
CM_ SG_ 80 SecAdNomALgtReqGroupSafeALgtNomReqMin "Secondary nominal longitudinal acceleration request Nominal acceleration req from HAD.";
CM_ SG_ 80 SecAdNomALgtReqGroupSafeChks "Secondary nominal longitudinal acceleration request E2E Checksum";
CM_ SG_ 80 SecAdNomALgtReqGroupSafeCntr "Secondary nominal longitudinal acceleration request E2E Counter";
CM_ SG_ 80 SecAdNomALgtReqGroupSafeNegLimForJerk "Secondary nominal longitudinal acceleration request Limit of maximum allowed negative jerk (acceleration rate of change)";
CM_ SG_ 80 SecAdNomALgtReqGroupSafePosLimForJerk "Secondary nominal longitudinal acceleration request Limit of maximum allowed positive jerk (acceleration rate of change)";
CM_ SG_ 768 SecAdWhlLockReqChks "Secondary AD request to lock wheels Checksum";
CM_ SG_ 768 SecAdWhlLockReqCntr "Secondary AD request to lock wheels Counter";
CM_ SG_ 768 SecAdWhlLockReqNoReqApplyRel "Secondary AD request to lock wheels NoReqApplyRel";
CM_ SG_ 40 SecMonTiSyncMsgChks "Used for validating Autosar time synchronization mechanism in SSMB. Profile VCC checksum";
CM_ SG_ 40 SecMonTiSyncMsgCntr "Used for validating Autosar time synchronization mechanism in SSMB. Profile VCC counter";
CM_ SG_ 40 SecMonTiSyncMsgTiStampNanoSec "Used for validating Autosar time synchronization mechanism in SSMB. Time stamp, nano seconds";
CM_ SG_ 40 SecMonTiSyncMsgTiStampSec "Used for validating Autosar time synchronization mechanism in SSMB. Time stamp, seconds";
BA_DEF_ BO_ "CANFD_BRS" ENUM "0","1";
BA_DEF_ BO_ "GenMsgCycleTime" INT 0 65536; // [ms]
BA_DEF_ BO_ "GenMsgDelayTime" INT 0 65536; // [ms]
BA_DEF_ BO_ "GenMsgSendType" ENUM "cyclic", "spontaneous", "not-used", "not-used", "not-used", "cyclicAndSpontaneous", "not-used", "cyclicIfActive", "NoMsgSendType"; // [us]
BA_DEF_ BO_ "GenMsgStartDelayTime" INT 0 65536; // [ms]
BA_DEF_ BO_ "VFrameFormat" ENUM "StandardCAN","ExtendedCAN","reserved","J1939PG","reserved","reserved","reserved","reserved","reserved","reserved","reserved","reserved","reserved","reserved","StandardCAN_FD","ExtendedCAN_FD";
BA_DEF_ SG_ "GenSigSendType" ENUM "Cyclic","OnWrite","OnWriteWithRepetition","OnChange","OnChangeWithRepetition","IfActive","IfActiveWithRepetition","NoSigSendType";
BA_DEF_ SG_ "GenSigStartValue" HEX 0 80000000;
BA_DEF_ BO_ "GenMsgILSupport" ENUM "No","Yes";
BA_DEF_ BO_ "NmAsrMessage" ENUM "No","Yes";
BA_DEF_ SG_ "GenSigFuncType" ENUM "NoFunction","n/a","n/a","n/a","n/a","n/a","n/a","n/a","n/a","n/a","n/a","n/a","n/a","n/a","n/a","CHK","CNTR","n/a","n/a","n/a","CNTR_AR_01","CRC_AR_01_BOTH","CRC_AR_01_ALT","CRC_AR_01_LOW","CRC_AR_01_NIBBLE","CNTR_AR_04","CRC_AR_04A","CNTR_AR_05","CRC_AR_05";
BA_DEF_ SG_ "GenSigDataID" STRING;
BA_DEF_DEF_ "CANFD_BRS" "1";
BA_DEF_DEF_ "GenSigStartValue" 0;
BA_DEF_DEF_ "VFrameFormat" "J1939PG";
BA_DEF_DEF_ "GenSigSendType" "NoSigSendType";
BA_DEF_DEF_ "GenMsgCycleTime" 0;
BA_DEF_DEF_ "GenMsgDelayTime" 0;
BA_DEF_DEF_ "GenMsgStartDelayTime" 0;
BA_DEF_DEF_ "GenMsgSendType" "NoMsgSendType";
BA_DEF_DEF_ "GenMsgILSupport" "Yes";
BA_DEF_DEF_ "NmAsrMessage" "No";
BA_DEF_DEF_ "GenSigFuncType" "NoFunction";
BA_DEF_DEF_ "GenSigDataID" "";
// Frame: VIMBMid6CanFdFr22
BA_ "GenMsgCycleTime" BO_ 283 90.000;
BA_ "GenMsgSendType" BO_ 283 0;
BA_ "VFrameFormat" BO_ 283 14;
// Frame: VIMBMid6CanFdFr23
BA_ "GenMsgCycleTime" BO_ 286 90.000;
BA_ "GenMsgSendType" BO_ 286 0;
BA_ "VFrameFormat" BO_ 286 14;
// Frame: VIMBMid6CanFdFr24
BA_ "GenMsgCycleTime" BO_ 289 90.000;
BA_ "GenMsgSendType" BO_ 289 0;
BA_ "VFrameFormat" BO_ 289 14;
// Frame: VIMBMid6CanFdFr25
BA_ "GenMsgCycleTime" BO_ 292 90.000;
BA_ "GenMsgSendType" BO_ 292 0;
BA_ "VFrameFormat" BO_ 292 14;
// Frame: VIMBMid6CanFdFr26
BA_ "GenMsgCycleTime" BO_ 295 90.000;
BA_ "GenMsgSendType" BO_ 295 0;
BA_ "VFrameFormat" BO_ 295 14;
// Frame: VIMBMid6CanFdFr27
BA_ "GenMsgCycleTime" BO_ 296 90.000;
BA_ "GenMsgSendType" BO_ 296 0;
BA_ "VFrameFormat" BO_ 296 14;
// Frame: VIMBMid6CanFdFr28
BA_ "GenMsgCycleTime" BO_ 80 10.000;
BA_ "GenMsgSendType" BO_ 80 0;
BA_ "VFrameFormat" BO_ 80 14;
// Frame: VIMBMid6CanFdFr29
BA_ "GenMsgCycleTime" BO_ 768 290.000;
BA_ "GenMsgSendType" BO_ 768 0;
BA_ "VFrameFormat" BO_ 768 14;
// Frame: VIMBPrototypeMid6CanFdFr29
BA_ "GenMsgDelayTime" BO_ 40 100.000;
BA_ "GenMsgSendType" BO_ 40 1;
BA_ "VFrameFormat" BO_ 40 14;
// Frame: VimbMid6CanFdTimeSynchFr
BA_ "GenMsgDelayTime" BO_ 64 20.000;
BA_ "GenMsgSendType" BO_ 64 1;
BA_ "VFrameFormat" BO_ 64 14;
BA_ "GenSigStartValue" SG_ 80 AdSecALgtLimReqGroupSafeALgtMaxReq 3840;
BA_ "GenSigDataID" SG_ 80 AdSecALgtLimReqGroupSafeChks "0x1C5";
BA_ "GenSigFuncType" SG_ 80 AdSecALgtLimReqGroupSafeChks 15;
BA_ "GenSigFuncType" SG_ 80 AdSecALgtLimReqGroupSafeCntr 16;
BA_ "GenSigDataID" SG_ 283 AdSecPSSGroupSafe3Chks "0x2C4";
BA_ "GenSigFuncType" SG_ 283 AdSecPSSGroupSafe3Chks 28;
BA_ "GenSigFuncType" SG_ 283 AdSecPSSGroupSafe3Cntr 27;
BA_ "GenSigStartValue" SG_ 283 AdSecPSSGroupSafe3DeltaXPos1 131070;
BA_ "GenSigStartValue" SG_ 283 AdSecPSSGroupSafe3DeltaXPos2 131070;
BA_ "GenSigStartValue" SG_ 283 AdSecPSSGroupSafe3DeltaXPos3 131070;
BA_ "GenSigStartValue" SG_ 283 AdSecPSSGroupSafe3DeltaXPos4 131070;
BA_ "GenSigStartValue" SG_ 283 AdSecPSSGroupSafe3DeltaXPos5 131070;
BA_ "GenSigStartValue" SG_ 283 AdSecPSSGroupSafe3DeltaXPos6 131070;
BA_ "GenSigStartValue" SG_ 283 AdSecPSSGroupSafe3DeltaYPos1 131070;
BA_ "GenSigStartValue" SG_ 283 AdSecPSSGroupSafe3DeltaYPos2 131070;
BA_ "GenSigStartValue" SG_ 283 AdSecPSSGroupSafe3DeltaYPos3 131070;
BA_ "GenSigStartValue" SG_ 283 AdSecPSSGroupSafe3DeltaYPos4 131070;
BA_ "GenSigStartValue" SG_ 283 AdSecPSSGroupSafe3DeltaYPos5 131070;
BA_ "GenSigStartValue" SG_ 283 AdSecPSSGroupSafe3DeltaYPos6 131070;
BA_ "GenSigStartValue" SG_ 283 AdSecPSSGroupSafe3HeadingPos1 32767;
BA_ "GenSigStartValue" SG_ 283 AdSecPSSGroupSafe3HeadingPos2 32767;
BA_ "GenSigStartValue" SG_ 283 AdSecPSSGroupSafe3HeadingPos3 32767;
BA_ "GenSigStartValue" SG_ 283 AdSecPSSGroupSafe3HeadingPos4 32767;
BA_ "GenSigStartValue" SG_ 283 AdSecPSSGroupSafe3HeadingPos5 32767;
BA_ "GenSigStartValue" SG_ 283 AdSecPSSGroupSafe3HeadingPos6 32767;
BA_ "GenSigDataID" SG_ 286 AdSecPSSGroupSafe4Chks "0x2C5";
BA_ "GenSigFuncType" SG_ 286 AdSecPSSGroupSafe4Chks 28;
BA_ "GenSigFuncType" SG_ 286 AdSecPSSGroupSafe4Cntr 27;
BA_ "GenSigStartValue" SG_ 286 AdSecPSSGroupSafe4DeltaXPos1 131070;
BA_ "GenSigStartValue" SG_ 286 AdSecPSSGroupSafe4DeltaXPos2 131070;
BA_ "GenSigStartValue" SG_ 286 AdSecPSSGroupSafe4DeltaXPos3 131070;
BA_ "GenSigStartValue" SG_ 286 AdSecPSSGroupSafe4DeltaXPos4 131070;
BA_ "GenSigStartValue" SG_ 286 AdSecPSSGroupSafe4DeltaXPos5 131070;
BA_ "GenSigStartValue" SG_ 286 AdSecPSSGroupSafe4DeltaXPos6 131070;
BA_ "GenSigStartValue" SG_ 286 AdSecPSSGroupSafe4DeltaYPos1 131070;
BA_ "GenSigStartValue" SG_ 286 AdSecPSSGroupSafe4DeltaYPos2 131070;
BA_ "GenSigStartValue" SG_ 286 AdSecPSSGroupSafe4DeltaYPos3 131070;
BA_ "GenSigStartValue" SG_ 286 AdSecPSSGroupSafe4DeltaYPos4 131070;
BA_ "GenSigStartValue" SG_ 286 AdSecPSSGroupSafe4DeltaYPos5 131070;
BA_ "GenSigStartValue" SG_ 286 AdSecPSSGroupSafe4DeltaYPos6 131070;
BA_ "GenSigStartValue" SG_ 286 AdSecPSSGroupSafe4HeadingPos1 32767;
BA_ "GenSigStartValue" SG_ 286 AdSecPSSGroupSafe4HeadingPos2 32767;
BA_ "GenSigStartValue" SG_ 286 AdSecPSSGroupSafe4HeadingPos3 32767;
BA_ "GenSigStartValue" SG_ 286 AdSecPSSGroupSafe4HeadingPos4 32767;
BA_ "GenSigStartValue" SG_ 286 AdSecPSSGroupSafe4HeadingPos5 32767;
BA_ "GenSigStartValue" SG_ 286 AdSecPSSGroupSafe4HeadingPos6 32767;
BA_ "GenSigDataID" SG_ 289 AdSecPSSGroupSafe5Chks "0x2C6";
BA_ "GenSigFuncType" SG_ 289 AdSecPSSGroupSafe5Chks 28;
BA_ "GenSigFuncType" SG_ 289 AdSecPSSGroupSafe5Cntr 27;
BA_ "GenSigStartValue" SG_ 289 AdSecPSSGroupSafe5DeltaXPos1 131070;
BA_ "GenSigStartValue" SG_ 289 AdSecPSSGroupSafe5DeltaXPos2 131070;
BA_ "GenSigStartValue" SG_ 289 AdSecPSSGroupSafe5DeltaXPos3 131070;
BA_ "GenSigStartValue" SG_ 289 AdSecPSSGroupSafe5DeltaXPos4 131070;
BA_ "GenSigStartValue" SG_ 289 AdSecPSSGroupSafe5DeltaXPos5 131070;
BA_ "GenSigStartValue" SG_ 289 AdSecPSSGroupSafe5DeltaXPos6 131070;
BA_ "GenSigStartValue" SG_ 289 AdSecPSSGroupSafe5DeltaYPos1 131070;
BA_ "GenSigStartValue" SG_ 289 AdSecPSSGroupSafe5DeltaYPos2 131070;
BA_ "GenSigStartValue" SG_ 289 AdSecPSSGroupSafe5DeltaYPos3 131070;
BA_ "GenSigStartValue" SG_ 289 AdSecPSSGroupSafe5DeltaYPos4 131070;
BA_ "GenSigStartValue" SG_ 289 AdSecPSSGroupSafe5DeltaYPos5 131070;
BA_ "GenSigStartValue" SG_ 289 AdSecPSSGroupSafe5DeltaYPos6 131070;
BA_ "GenSigStartValue" SG_ 289 AdSecPSSGroupSafe5HeadingPos1 32767;
BA_ "GenSigStartValue" SG_ 289 AdSecPSSGroupSafe5HeadingPos2 32767;
BA_ "GenSigStartValue" SG_ 289 AdSecPSSGroupSafe5HeadingPos3 32767;
BA_ "GenSigStartValue" SG_ 289 AdSecPSSGroupSafe5HeadingPos4 32767;
BA_ "GenSigStartValue" SG_ 289 AdSecPSSGroupSafe5HeadingPos5 32767;
BA_ "GenSigStartValue" SG_ 289 AdSecPSSGroupSafe5HeadingPos6 32767;
BA_ "GenSigDataID" SG_ 292 AdSecPSSGroupSafe6Chks "0x2CA";
BA_ "GenSigFuncType" SG_ 292 AdSecPSSGroupSafe6Chks 28;
BA_ "GenSigFuncType" SG_ 292 AdSecPSSGroupSafe6Cntr 27;
BA_ "GenSigStartValue" SG_ 292 AdSecPSSGroupSafe6DeltaXPos1 131070;
BA_ "GenSigStartValue" SG_ 292 AdSecPSSGroupSafe6DeltaXPos2 131070;
BA_ "GenSigStartValue" SG_ 292 AdSecPSSGroupSafe6DeltaXPos3 131070;
BA_ "GenSigStartValue" SG_ 292 AdSecPSSGroupSafe6DeltaXPos4 131070;
BA_ "GenSigStartValue" SG_ 292 AdSecPSSGroupSafe6DeltaXPos5 131070;
BA_ "GenSigStartValue" SG_ 292 AdSecPSSGroupSafe6DeltaXPos6 131070;
BA_ "GenSigStartValue" SG_ 292 AdSecPSSGroupSafe6DeltaYPos1 131070;
BA_ "GenSigStartValue" SG_ 292 AdSecPSSGroupSafe6DeltaYPos2 131070;
BA_ "GenSigStartValue" SG_ 292 AdSecPSSGroupSafe6DeltaYPos3 131070;
BA_ "GenSigStartValue" SG_ 292 AdSecPSSGroupSafe6DeltaYPos4 131070;
BA_ "GenSigStartValue" SG_ 292 AdSecPSSGroupSafe6DeltaYPos5 131070;
BA_ "GenSigStartValue" SG_ 292 AdSecPSSGroupSafe6DeltaYPos6 131070;
BA_ "GenSigStartValue" SG_ 292 AdSecPSSGroupSafe6HeadingPos1 32767;
BA_ "GenSigStartValue" SG_ 292 AdSecPSSGroupSafe6HeadingPos2 32767;
BA_ "GenSigStartValue" SG_ 292 AdSecPSSGroupSafe6HeadingPos3 32767;
BA_ "GenSigStartValue" SG_ 292 AdSecPSSGroupSafe6HeadingPos4 32767;
BA_ "GenSigStartValue" SG_ 292 AdSecPSSGroupSafe6HeadingPos5 32767;
BA_ "GenSigStartValue" SG_ 292 AdSecPSSGroupSafe6HeadingPos6 32767;
BA_ "GenSigDataID" SG_ 295 AdSecPSSGroupSafe7Chks "0x2CB";
BA_ "GenSigFuncType" SG_ 295 AdSecPSSGroupSafe7Chks 28;
BA_ "GenSigFuncType" SG_ 295 AdSecPSSGroupSafe7Cntr 27;
BA_ "GenSigStartValue" SG_ 295 AdSecPSSGroupSafe7DeltaXPos1 131070;
BA_ "GenSigStartValue" SG_ 295 AdSecPSSGroupSafe7DeltaXPos2 131070;
BA_ "GenSigStartValue" SG_ 295 AdSecPSSGroupSafe7DeltaXPos3 131070;
BA_ "GenSigStartValue" SG_ 295 AdSecPSSGroupSafe7DeltaXPos4 131070;
BA_ "GenSigStartValue" SG_ 295 AdSecPSSGroupSafe7DeltaXPos5 131070;
BA_ "GenSigStartValue" SG_ 295 AdSecPSSGroupSafe7DeltaXPos6 131070;
BA_ "GenSigStartValue" SG_ 295 AdSecPSSGroupSafe7DeltaYPos1 131070;
BA_ "GenSigStartValue" SG_ 295 AdSecPSSGroupSafe7DeltaYPos2 131070;
BA_ "GenSigStartValue" SG_ 295 AdSecPSSGroupSafe7DeltaYPos3 131070;
BA_ "GenSigStartValue" SG_ 295 AdSecPSSGroupSafe7DeltaYPos4 131070;
BA_ "GenSigStartValue" SG_ 295 AdSecPSSGroupSafe7DeltaYPos5 131070;
BA_ "GenSigStartValue" SG_ 295 AdSecPSSGroupSafe7DeltaYPos6 131070;
BA_ "GenSigStartValue" SG_ 295 AdSecPSSGroupSafe7HeadingPos1 32767;
BA_ "GenSigStartValue" SG_ 295 AdSecPSSGroupSafe7HeadingPos2 32767;
BA_ "GenSigStartValue" SG_ 295 AdSecPSSGroupSafe7HeadingPos3 32767;
BA_ "GenSigStartValue" SG_ 295 AdSecPSSGroupSafe7HeadingPos4 32767;
BA_ "GenSigStartValue" SG_ 295 AdSecPSSGroupSafe7HeadingPos5 32767;
BA_ "GenSigStartValue" SG_ 295 AdSecPSSGroupSafe7HeadingPos6 32767;
BA_ "GenSigDataID" SG_ 296 AdSecPSSGroupSafe8Chks "0x423";
BA_ "GenSigFuncType" SG_ 296 AdSecPSSGroupSafe8Chks 28;
BA_ "GenSigFuncType" SG_ 296 AdSecPSSGroupSafe8Cntr 27;
BA_ "GenSigStartValue" SG_ 296 AdSecPSSGroupSafe8DeltaXPos1 131070;
BA_ "GenSigStartValue" SG_ 296 AdSecPSSGroupSafe8DeltaXPos2 131070;
BA_ "GenSigStartValue" SG_ 296 AdSecPSSGroupSafe8DeltaXPos3 131070;
BA_ "GenSigStartValue" SG_ 296 AdSecPSSGroupSafe8DeltaXPos4 131070;
BA_ "GenSigStartValue" SG_ 296 AdSecPSSGroupSafe8DeltaXPos5 131070;
BA_ "GenSigStartValue" SG_ 296 AdSecPSSGroupSafe8DeltaXPos6 131070;
BA_ "GenSigStartValue" SG_ 296 AdSecPSSGroupSafe8DeltaYPos1 131070;
BA_ "GenSigStartValue" SG_ 296 AdSecPSSGroupSafe8DeltaYPos2 131070;
BA_ "GenSigStartValue" SG_ 296 AdSecPSSGroupSafe8DeltaYPos3 131070;
BA_ "GenSigStartValue" SG_ 296 AdSecPSSGroupSafe8DeltaYPos4 131070;
BA_ "GenSigStartValue" SG_ 296 AdSecPSSGroupSafe8DeltaYPos5 131070;
BA_ "GenSigStartValue" SG_ 296 AdSecPSSGroupSafe8DeltaYPos6 131070;
BA_ "GenSigStartValue" SG_ 296 AdSecPSSGroupSafe8HeadingPos1 32767;
BA_ "GenSigStartValue" SG_ 296 AdSecPSSGroupSafe8HeadingPos2 32767;
BA_ "GenSigStartValue" SG_ 296 AdSecPSSGroupSafe8HeadingPos3 32767;
BA_ "GenSigStartValue" SG_ 296 AdSecPSSGroupSafe8HeadingPos4 32767;
BA_ "GenSigStartValue" SG_ 296 AdSecPSSGroupSafe8HeadingPos5 32767;
BA_ "GenSigStartValue" SG_ 296 AdSecPSSGroupSafe8HeadingPos6 32767;
BA_ "GenSigStartValue" SG_ 80 SecAdNomALgtReqGroupSafeALgtNomReqMax 1920;
BA_ "GenSigStartValue" SG_ 80 SecAdNomALgtReqGroupSafeALgtNomReqMin 1920;
BA_ "GenSigDataID" SG_ 80 SecAdNomALgtReqGroupSafeChks "0x2AA";
BA_ "GenSigFuncType" SG_ 80 SecAdNomALgtReqGroupSafeChks 15;
BA_ "GenSigFuncType" SG_ 80 SecAdNomALgtReqGroupSafeCntr 16;
BA_ "GenSigStartValue" SG_ 80 SecAdNomALgtReqGroupSafeNegLimForJerk 2000;
BA_ "GenSigStartValue" SG_ 80 SecAdNomALgtReqGroupSafePosLimForJerk 2000;
BA_ "GenSigDataID" SG_ 768 SecAdWhlLockReqChks "0x710";
BA_ "GenSigFuncType" SG_ 768 SecAdWhlLockReqChks 15;
BA_ "GenSigFuncType" SG_ 768 SecAdWhlLockReqCntr 16;
BA_ "GenSigDataID" SG_ 40 SecMonTiSyncMsgChks "0x71D";
BA_ "GenSigFuncType" SG_ 40 SecMonTiSyncMsgChks 15;
BA_ "GenSigSendType" SG_ 40 SecMonTiSyncMsgChks 1;
BA_ "GenSigFuncType" SG_ 40 SecMonTiSyncMsgCntr 16;
BA_ "GenSigSendType" SG_ 40 SecMonTiSyncMsgCntr 1;
BA_ "GenSigSendType" SG_ 40 SecMonTiSyncMsgTiStampNanoSec 1;
BA_ "GenSigSendType" SG_ 40 SecMonTiSyncMsgTiStampSec 1;
VAL_ 768 SecAdWhlLockReqNoReqApplyRel 0 "NoReqApplyRels1_NoReq" 1 "NoReqApplyRels1_Apply" 2 "NoReqApplyRels1_Rels";
SIG_GROUP_ 80 AdSecALgtLimReqGroupSafe 1 : AdSecALgtLimReqGroupSafeALgtMaxReq AdSecALgtLimReqGroupSafeALgtMinReq AdSecALgtLimReqGroupSafeChks AdSecALgtLimReqGroupSafeCntr;
SIG_GROUP_ 283 AdSecPSSGroupSafe3 1 : AdSecPSSGroupSafe3Chks AdSecPSSGroupSafe3Cntr AdSecPSSGroupSafe3DataID AdSecPSSGroupSafe3DeltaTPos1 AdSecPSSGroupSafe3DeltaTPos2 AdSecPSSGroupSafe3DeltaTPos3 AdSecPSSGroupSafe3DeltaTPos4 AdSecPSSGroupSafe3DeltaTPos5 AdSecPSSGroupSafe3DeltaTPos6 AdSecPSSGroupSafe3DeltaXPos1 AdSecPSSGroupSafe3DeltaXPos2 AdSecPSSGroupSafe3DeltaXPos3 AdSecPSSGroupSafe3DeltaXPos4 AdSecPSSGroupSafe3DeltaXPos5 AdSecPSSGroupSafe3DeltaXPos6 AdSecPSSGroupSafe3DeltaYPos1 AdSecPSSGroupSafe3DeltaYPos2 AdSecPSSGroupSafe3DeltaYPos3 AdSecPSSGroupSafe3DeltaYPos4 AdSecPSSGroupSafe3DeltaYPos5 AdSecPSSGroupSafe3DeltaYPos6 AdSecPSSGroupSafe3HeadingPos1 AdSecPSSGroupSafe3HeadingPos2 AdSecPSSGroupSafe3HeadingPos3 AdSecPSSGroupSafe3HeadingPos4 AdSecPSSGroupSafe3HeadingPos5 AdSecPSSGroupSafe3HeadingPos6 AdSecPSSGroupSafe3TrajectID;
SIG_GROUP_ 286 AdSecPSSGroupSafe4 1 : AdSecPSSGroupSafe4Chks AdSecPSSGroupSafe4Cntr AdSecPSSGroupSafe4DataID AdSecPSSGroupSafe4DeltaTPos1 AdSecPSSGroupSafe4DeltaTPos2 AdSecPSSGroupSafe4DeltaTPos3 AdSecPSSGroupSafe4DeltaTPos4 AdSecPSSGroupSafe4DeltaTPos5 AdSecPSSGroupSafe4DeltaTPos6 AdSecPSSGroupSafe4DeltaXPos1 AdSecPSSGroupSafe4DeltaXPos2 AdSecPSSGroupSafe4DeltaXPos3 AdSecPSSGroupSafe4DeltaXPos4 AdSecPSSGroupSafe4DeltaXPos5 AdSecPSSGroupSafe4DeltaXPos6 AdSecPSSGroupSafe4DeltaYPos1 AdSecPSSGroupSafe4DeltaYPos2 AdSecPSSGroupSafe4DeltaYPos3 AdSecPSSGroupSafe4DeltaYPos4 AdSecPSSGroupSafe4DeltaYPos5 AdSecPSSGroupSafe4DeltaYPos6 AdSecPSSGroupSafe4HeadingPos1 AdSecPSSGroupSafe4HeadingPos2 AdSecPSSGroupSafe4HeadingPos3 AdSecPSSGroupSafe4HeadingPos4 AdSecPSSGroupSafe4HeadingPos5 AdSecPSSGroupSafe4HeadingPos6 AdSecPSSGroupSafe4TrajectID;
SIG_GROUP_ 289 AdSecPSSGroupSafe5 1 : AdSecPSSGroupSafe5Chks AdSecPSSGroupSafe5Cntr AdSecPSSGroupSafe5DataID AdSecPSSGroupSafe5DeltaTPos1 AdSecPSSGroupSafe5DeltaTPos2 AdSecPSSGroupSafe5DeltaTPos3 AdSecPSSGroupSafe5DeltaTPos4 AdSecPSSGroupSafe5DeltaTPos5 AdSecPSSGroupSafe5DeltaTPos6 AdSecPSSGroupSafe5DeltaXPos1 AdSecPSSGroupSafe5DeltaXPos2 AdSecPSSGroupSafe5DeltaXPos3 AdSecPSSGroupSafe5DeltaXPos4 AdSecPSSGroupSafe5DeltaXPos5 AdSecPSSGroupSafe5DeltaXPos6 AdSecPSSGroupSafe5DeltaYPos1 AdSecPSSGroupSafe5DeltaYPos2 AdSecPSSGroupSafe5DeltaYPos3 AdSecPSSGroupSafe5DeltaYPos4 AdSecPSSGroupSafe5DeltaYPos5 AdSecPSSGroupSafe5DeltaYPos6 AdSecPSSGroupSafe5HeadingPos1 AdSecPSSGroupSafe5HeadingPos2 AdSecPSSGroupSafe5HeadingPos3 AdSecPSSGroupSafe5HeadingPos4 AdSecPSSGroupSafe5HeadingPos5 AdSecPSSGroupSafe5HeadingPos6 AdSecPSSGroupSafe5TrajectID;
SIG_GROUP_ 292 AdSecPSSGroupSafe6 1 : AdSecPSSGroupSafe6Chks AdSecPSSGroupSafe6Cntr AdSecPSSGroupSafe6DataID AdSecPSSGroupSafe6DeltaTPos1 AdSecPSSGroupSafe6DeltaTPos2 AdSecPSSGroupSafe6DeltaTPos3 AdSecPSSGroupSafe6DeltaTPos4 AdSecPSSGroupSafe6DeltaTPos5 AdSecPSSGroupSafe6DeltaTPos6 AdSecPSSGroupSafe6DeltaXPos1 AdSecPSSGroupSafe6DeltaXPos2 AdSecPSSGroupSafe6DeltaXPos3 AdSecPSSGroupSafe6DeltaXPos4 AdSecPSSGroupSafe6DeltaXPos5 AdSecPSSGroupSafe6DeltaXPos6 AdSecPSSGroupSafe6DeltaYPos1 AdSecPSSGroupSafe6DeltaYPos2 AdSecPSSGroupSafe6DeltaYPos3 AdSecPSSGroupSafe6DeltaYPos4 AdSecPSSGroupSafe6DeltaYPos5 AdSecPSSGroupSafe6DeltaYPos6 AdSecPSSGroupSafe6HeadingPos1 AdSecPSSGroupSafe6HeadingPos2 AdSecPSSGroupSafe6HeadingPos3 AdSecPSSGroupSafe6HeadingPos4 AdSecPSSGroupSafe6HeadingPos5 AdSecPSSGroupSafe6HeadingPos6 AdSecPSSGroupSafe6TrajectID;
SIG_GROUP_ 295 AdSecPSSGroupSafe7 1 : AdSecPSSGroupSafe7Chks AdSecPSSGroupSafe7Cntr AdSecPSSGroupSafe7DataID AdSecPSSGroupSafe7DeltaTPos1 AdSecPSSGroupSafe7DeltaTPos2 AdSecPSSGroupSafe7DeltaTPos3 AdSecPSSGroupSafe7DeltaTPos4 AdSecPSSGroupSafe7DeltaTPos5 AdSecPSSGroupSafe7DeltaTPos6 AdSecPSSGroupSafe7DeltaXPos1 AdSecPSSGroupSafe7DeltaXPos2 AdSecPSSGroupSafe7DeltaXPos3 AdSecPSSGroupSafe7DeltaXPos4 AdSecPSSGroupSafe7DeltaXPos5 AdSecPSSGroupSafe7DeltaXPos6 AdSecPSSGroupSafe7DeltaYPos1 AdSecPSSGroupSafe7DeltaYPos2 AdSecPSSGroupSafe7DeltaYPos3 AdSecPSSGroupSafe7DeltaYPos4 AdSecPSSGroupSafe7DeltaYPos5 AdSecPSSGroupSafe7DeltaYPos6 AdSecPSSGroupSafe7HeadingPos1 AdSecPSSGroupSafe7HeadingPos2 AdSecPSSGroupSafe7HeadingPos3 AdSecPSSGroupSafe7HeadingPos4 AdSecPSSGroupSafe7HeadingPos5 AdSecPSSGroupSafe7HeadingPos6 AdSecPSSGroupSafe7TrajectID;
SIG_GROUP_ 296 AdSecPSSGroupSafe8 1 : AdSecPSSGroupSafe8Chks AdSecPSSGroupSafe8Cntr AdSecPSSGroupSafe8DataID AdSecPSSGroupSafe8DeltaTPos1 AdSecPSSGroupSafe8DeltaTPos2 AdSecPSSGroupSafe8DeltaTPos3 AdSecPSSGroupSafe8DeltaTPos4 AdSecPSSGroupSafe8DeltaTPos5 AdSecPSSGroupSafe8DeltaTPos6 AdSecPSSGroupSafe8DeltaXPos1 AdSecPSSGroupSafe8DeltaXPos2 AdSecPSSGroupSafe8DeltaXPos3 AdSecPSSGroupSafe8DeltaXPos4 AdSecPSSGroupSafe8DeltaXPos5 AdSecPSSGroupSafe8DeltaXPos6 AdSecPSSGroupSafe8DeltaYPos1 AdSecPSSGroupSafe8DeltaYPos2 AdSecPSSGroupSafe8DeltaYPos3 AdSecPSSGroupSafe8DeltaYPos4 AdSecPSSGroupSafe8DeltaYPos5 AdSecPSSGroupSafe8DeltaYPos6 AdSecPSSGroupSafe8HeadingPos1 AdSecPSSGroupSafe8HeadingPos2 AdSecPSSGroupSafe8HeadingPos3 AdSecPSSGroupSafe8HeadingPos4 AdSecPSSGroupSafe8HeadingPos5 AdSecPSSGroupSafe8HeadingPos6 AdSecPSSGroupSafe8TrajectID;
SIG_GROUP_ 80 SecAdNomALgtReqGroupSafe 1 : SecAdNomALgtReqGroupSafeALgtNomReqMax SecAdNomALgtReqGroupSafeALgtNomReqMin SecAdNomALgtReqGroupSafeChks SecAdNomALgtReqGroupSafeCntr SecAdNomALgtReqGroupSafeNegLimForJerk SecAdNomALgtReqGroupSafePosLimForJerk;
SIG_GROUP_ 768 SecAdWhlLockReq 1 : SecAdWhlLockReqChks SecAdWhlLockReqCntr SecAdWhlLockReqNoReqApplyRel;
SIG_GROUP_ 40 SecMonTiSyncMsg 1 : SecMonTiSyncMsgChks SecMonTiSyncMsgCntr SecMonTiSyncMsgTiStampNanoSec SecMonTiSyncMsgTiStampSec;
